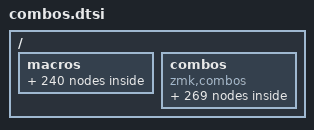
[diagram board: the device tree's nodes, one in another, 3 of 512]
// Chords (combos) for common English words and utility keys
//
// Key position reference (QWERTY) — Ergonaut One 42-key:
//  0(])  1(Q)  2(W)  3(E)  4(R)  5(T)  |  6(Y)  7(U)  8(I)  9(O) 10(P) 11([)
// 12(`) 13(A) 14(S) 15(D) 16(F) 17(G)  | 18(H) 19(J) 20(K) 21(L) 22(;) 23(')
// 24(-) 25(Z) 26(X) 27(C) 28(V) 29(B)  | 30(N) 31(M) 32(,) 33(.) 34(/) 35(\)
//                   36    37    38      | 39    40    41
//
// Letter positions: A=13 B=29 C=27 D=15 E=3 F=16 G=17 H=18 I=8 J=19 K=20
//                   L=21 M=31 N=30 O=9 P=10 Q=1 R=4 S=14 T=5 U=7 V=28
//                   W=2 X=26 Y=6 Z=25
//
// Word combos: timeout-ms=40, require-prior-idle-ms=150, layer 0 only.
// Utility combos: timeout-ms=30, no prior-idle, layer 0 only.
//
// 2-key conflict resolutions (ZMK combos are order-independent):
//   N+T kept as "not", dropped "then" (T+N)
//   T+M kept as "time", dropped "most" (M+T)
//   W+N kept as "when", dropped "new" (N+W)
// 3-key conflict resolutions (6 dropped):
//   Combos sharing identical sorted key sets with a 2-key or another 3-key
//   combo were resolved by keeping the higher-priority entry.

/ {
    macros {
        // === 2-key word macros (58) ===
        m_the: m_the { compatible = "zmk,behavior-macro"; #binding-cells = <0>; wait-ms = <10>; tap-ms = <10>;
            bindings = <&kp T &kp H &kp E &kp SPACE>; };
        m_and: m_and { compatible = "zmk,behavior-macro"; #binding-cells = <0>; wait-ms = <10>; tap-ms = <10>;
            bindings = <&kp A &kp N &kp D &kp SPACE>; };
        m_that: m_that { compatible = "zmk,behavior-macro"; #binding-cells = <0>; wait-ms = <10>; tap-ms = <10>;
            bindings = <&kp T &kp H &kp A &kp T &kp SPACE>; };
        m_have: m_have { compatible = "zmk,behavior-macro"; #binding-cells = <0>; wait-ms = <10>; tap-ms = <10>;
            bindings = <&kp H &kp A &kp V &kp E &kp SPACE>; };
        m_with: m_with { compatible = "zmk,behavior-macro"; #binding-cells = <0>; wait-ms = <10>; tap-ms = <10>;
            bindings = <&kp W &kp I &kp T &kp H &kp SPACE>; };
        m_for: m_for { compatible = "zmk,behavior-macro"; #binding-cells = <0>; wait-ms = <10>; tap-ms = <10>;
            bindings = <&kp F &kp O &kp R &kp SPACE>; };
        m_not: m_not { compatible = "zmk,behavior-macro"; #binding-cells = <0>; wait-ms = <10>; tap-ms = <10>;
            bindings = <&kp N &kp O &kp T &kp SPACE>; };
        m_you: m_you { compatible = "zmk,behavior-macro"; #binding-cells = <0>; wait-ms = <10>; tap-ms = <10>;
            bindings = <&kp Y &kp O &kp U &kp SPACE>; };
        m_this: m_this { compatible = "zmk,behavior-macro"; #binding-cells = <0>; wait-ms = <10>; tap-ms = <10>;
            bindings = <&kp T &kp H &kp I &kp S &kp SPACE>; };
        m_but: m_but { compatible = "zmk,behavior-macro"; #binding-cells = <0>; wait-ms = <10>; tap-ms = <10>;
            bindings = <&kp B &kp U &kp T &kp SPACE>; };
        m_from: m_from { compatible = "zmk,behavior-macro"; #binding-cells = <0>; wait-ms = <10>; tap-ms = <10>;
            bindings = <&kp F &kp R &kp O &kp M &kp SPACE>; };
        m_they: m_they { compatible = "zmk,behavior-macro"; #binding-cells = <0>; wait-ms = <10>; tap-ms = <10>;
            bindings = <&kp T &kp H &kp E &kp Y &kp SPACE>; };
        m_will: m_will { compatible = "zmk,behavior-macro"; #binding-cells = <0>; wait-ms = <10>; tap-ms = <10>;
            bindings = <&kp W &kp I &kp L &kp L &kp SPACE>; };
        m_would: m_would { compatible = "zmk,behavior-macro"; #binding-cells = <0>; wait-ms = <10>; tap-ms = <10>;
            bindings = <&kp W &kp O &kp U &kp L &kp D &kp SPACE>; };
        m_what: m_what { compatible = "zmk,behavior-macro"; #binding-cells = <0>; wait-ms = <10>; tap-ms = <10>;
            bindings = <&kp W &kp H &kp A &kp T &kp SPACE>; };
        m_about: m_about { compatible = "zmk,behavior-macro"; #binding-cells = <0>; wait-ms = <10>; tap-ms = <10>;
            bindings = <&kp A &kp B &kp O &kp U &kp T &kp SPACE>; };
        m_which: m_which { compatible = "zmk,behavior-macro"; #binding-cells = <0>; wait-ms = <10>; tap-ms = <10>;
            bindings = <&kp W &kp H &kp I &kp C &kp H &kp SPACE>; };
        m_when: m_when { compatible = "zmk,behavior-macro"; #binding-cells = <0>; wait-ms = <10>; tap-ms = <10>;
            bindings = <&kp W &kp H &kp E &kp N &kp SPACE>; };
        m_just: m_just { compatible = "zmk,behavior-macro"; #binding-cells = <0>; wait-ms = <10>; tap-ms = <10>;
            bindings = <&kp J &kp U &kp S &kp T &kp SPACE>; };
        m_know: m_know { compatible = "zmk,behavior-macro"; #binding-cells = <0>; wait-ms = <10>; tap-ms = <10>;
            bindings = <&kp K &kp N &kp O &kp W &kp SPACE>; };
        m_like: m_like { compatible = "zmk,behavior-macro"; #binding-cells = <0>; wait-ms = <10>; tap-ms = <10>;
            bindings = <&kp L &kp I &kp K &kp E &kp SPACE>; };
        m_your: m_your { compatible = "zmk,behavior-macro"; #binding-cells = <0>; wait-ms = <10>; tap-ms = <10>;
            bindings = <&kp Y &kp O &kp U &kp R &kp SPACE>; };
        m_could: m_could { compatible = "zmk,behavior-macro"; #binding-cells = <0>; wait-ms = <10>; tap-ms = <10>;
            bindings = <&kp C &kp O &kp U &kp L &kp D &kp SPACE>; };
        m_should: m_should { compatible = "zmk,behavior-macro"; #binding-cells = <0>; wait-ms = <10>; tap-ms = <10>;
            bindings = <&kp S &kp H &kp O &kp U &kp L &kp D &kp SPACE>; };
        m_before: m_before { compatible = "zmk,behavior-macro"; #binding-cells = <0>; wait-ms = <10>; tap-ms = <10>;
            bindings = <&kp B &kp E &kp F &kp O &kp R &kp E &kp SPACE>; };
        m_because: m_because { compatible = "zmk,behavior-macro"; #binding-cells = <0>; wait-ms = <10>; tap-ms = <10>;
            bindings = <&kp B &kp E &kp C &kp A &kp U &kp S &kp E &kp SPACE>; };
        m_think: m_think { compatible = "zmk,behavior-macro"; #binding-cells = <0>; wait-ms = <10>; tap-ms = <10>;
            bindings = <&kp T &kp H &kp I &kp N &kp K &kp SPACE>; };
        m_also: m_also { compatible = "zmk,behavior-macro"; #binding-cells = <0>; wait-ms = <10>; tap-ms = <10>;
            bindings = <&kp A &kp L &kp S &kp O &kp SPACE>; };
        m_after: m_after { compatible = "zmk,behavior-macro"; #binding-cells = <0>; wait-ms = <10>; tap-ms = <10>;
            bindings = <&kp A &kp F &kp T &kp E &kp R &kp SPACE>; };
        m_time: m_time { compatible = "zmk,behavior-macro"; #binding-cells = <0>; wait-ms = <10>; tap-ms = <10>;
            bindings = <&kp T &kp I &kp M &kp E &kp SPACE>; };
        m_again: m_again { compatible = "zmk,behavior-macro"; #binding-cells = <0>; wait-ms = <10>; tap-ms = <10>;
            bindings = <&kp A &kp G &kp A &kp I &kp N &kp SPACE>; };
        m_some: m_some { compatible = "zmk,behavior-macro"; #binding-cells = <0>; wait-ms = <10>; tap-ms = <10>;
            bindings = <&kp S &kp O &kp M &kp E &kp SPACE>; };
        m_good: m_good { compatible = "zmk,behavior-macro"; #binding-cells = <0>; wait-ms = <10>; tap-ms = <10>;
            bindings = <&kp G &kp O &kp O &kp D &kp SPACE>; };
        m_more: m_more { compatible = "zmk,behavior-macro"; #binding-cells = <0>; wait-ms = <10>; tap-ms = <10>;
            bindings = <&kp M &kp O &kp R &kp E &kp SPACE>; };
        m_never: m_never { compatible = "zmk,behavior-macro"; #binding-cells = <0>; wait-ms = <10>; tap-ms = <10>;
            bindings = <&kp N &kp E &kp V &kp E &kp R &kp SPACE>; };
        m_even: m_even { compatible = "zmk,behavior-macro"; #binding-cells = <0>; wait-ms = <10>; tap-ms = <10>;
            bindings = <&kp E &kp V &kp E &kp N &kp SPACE>; };
        m_very: m_very { compatible = "zmk,behavior-macro"; #binding-cells = <0>; wait-ms = <10>; tap-ms = <10>;
            bindings = <&kp V &kp E &kp R &kp Y &kp SPACE>; };
        m_work: m_work { compatible = "zmk,behavior-macro"; #binding-cells = <0>; wait-ms = <10>; tap-ms = <10>;
            bindings = <&kp W &kp O &kp R &kp K &kp SPACE>; };
        m_way: m_way { compatible = "zmk,behavior-macro"; #binding-cells = <0>; wait-ms = <10>; tap-ms = <10>;
            bindings = <&kp W &kp A &kp Y &kp SPACE>; };
        m_make: m_make { compatible = "zmk,behavior-macro"; #binding-cells = <0>; wait-ms = <10>; tap-ms = <10>;
            bindings = <&kp M &kp A &kp K &kp E &kp SPACE>; };
        m_need: m_need { compatible = "zmk,behavior-macro"; #binding-cells = <0>; wait-ms = <10>; tap-ms = <10>;
            bindings = <&kp N &kp E &kp E &kp D &kp SPACE>; };
        m_only: m_only { compatible = "zmk,behavior-macro"; #binding-cells = <0>; wait-ms = <10>; tap-ms = <10>;
            bindings = <&kp O &kp N &kp L &kp Y &kp SPACE>; };
        m_been: m_been { compatible = "zmk,behavior-macro"; #binding-cells = <0>; wait-ms = <10>; tap-ms = <10>;
            bindings = <&kp B &kp E &kp E &kp N &kp SPACE>; };
        m_while: m_while { compatible = "zmk,behavior-macro"; #binding-cells = <0>; wait-ms = <10>; tap-ms = <10>;
            bindings = <&kp W &kp H &kp I &kp L &kp E &kp SPACE>; };
        m_can: m_can { compatible = "zmk,behavior-macro"; #binding-cells = <0>; wait-ms = <10>; tap-ms = <10>;
            bindings = <&kp C &kp A &kp N &kp SPACE>; };
        m_come: m_come { compatible = "zmk,behavior-macro"; #binding-cells = <0>; wait-ms = <10>; tap-ms = <10>;
            bindings = <&kp C &kp O &kp M &kp E &kp SPACE>; };
        m_one: m_one { compatible = "zmk,behavior-macro"; #binding-cells = <0>; wait-ms = <10>; tap-ms = <10>;
            bindings = <&kp O &kp N &kp E &kp SPACE>; };
        m_great: m_great { compatible = "zmk,behavior-macro"; #binding-cells = <0>; wait-ms = <10>; tap-ms = <10>;
            bindings = <&kp G &kp R &kp E &kp A &kp T &kp SPACE>; };
        m_might: m_might { compatible = "zmk,behavior-macro"; #binding-cells = <0>; wait-ms = <10>; tap-ms = <10>;
            bindings = <&kp M &kp I &kp G &kp H &kp T &kp SPACE>; };
        m_found: m_found { compatible = "zmk,behavior-macro"; #binding-cells = <0>; wait-ms = <10>; tap-ms = <10>;
            bindings = <&kp F &kp O &kp U &kp N &kp D &kp SPACE>; };
        m_under: m_under { compatible = "zmk,behavior-macro"; #binding-cells = <0>; wait-ms = <10>; tap-ms = <10>;
            bindings = <&kp U &kp N &kp D &kp E &kp R &kp SPACE>; };
        m_other: m_other { compatible = "zmk,behavior-macro"; #binding-cells = <0>; wait-ms = <10>; tap-ms = <10>;
            bindings = <&kp O &kp T &kp H &kp E &kp R &kp SPACE>; };
        m_people: m_people { compatible = "zmk,behavior-macro"; #binding-cells = <0>; wait-ms = <10>; tap-ms = <10>;
            bindings = <&kp P &kp E &kp O &kp P &kp L &kp E &kp SPACE>; };
        m_really: m_really { compatible = "zmk,behavior-macro"; #binding-cells = <0>; wait-ms = <10>; tap-ms = <10>;
            bindings = <&kp R &kp E &kp A &kp L &kp L &kp Y &kp SPACE>; };
        m_her: m_her { compatible = "zmk,behavior-macro"; #binding-cells = <0>; wait-ms = <10>; tap-ms = <10>;
            bindings = <&kp H &kp E &kp R &kp SPACE>; };
        m_his: m_his { compatible = "zmk,behavior-macro"; #binding-cells = <0>; wait-ms = <10>; tap-ms = <10>;
            bindings = <&kp H &kp I &kp S &kp SPACE>; };
        m_are: m_are { compatible = "zmk,behavior-macro"; #binding-cells = <0>; wait-ms = <10>; tap-ms = <10>;
            bindings = <&kp A &kp R &kp E &kp SPACE>; };
        m_was: m_was { compatible = "zmk,behavior-macro"; #binding-cells = <0>; wait-ms = <10>; tap-ms = <10>;
            bindings = <&kp W &kp A &kp S &kp SPACE>; };

        // === 3-key word macros — Common English (43) ===
        m_through: m_through { compatible = "zmk,behavior-macro"; #binding-cells = <0>; wait-ms = <10>; tap-ms = <10>;
            bindings = <&kp T &kp H &kp R &kp O &kp U &kp G &kp H &kp SPACE>; };
        m_there: m_there { compatible = "zmk,behavior-macro"; #binding-cells = <0>; wait-ms = <10>; tap-ms = <10>;
            bindings = <&kp T &kp H &kp E &kp R &kp E &kp SPACE>; };
        m_than: m_than { compatible = "zmk,behavior-macro"; #binding-cells = <0>; wait-ms = <10>; tap-ms = <10>;
            bindings = <&kp T &kp H &kp A &kp N &kp SPACE>; };
        m_their: m_their { compatible = "zmk,behavior-macro"; #binding-cells = <0>; wait-ms = <10>; tap-ms = <10>;
            bindings = <&kp T &kp H &kp E &kp I &kp R &kp SPACE>; };
        m_those: m_those { compatible = "zmk,behavior-macro"; #binding-cells = <0>; wait-ms = <10>; tap-ms = <10>;
            bindings = <&kp T &kp H &kp O &kp S &kp E &kp SPACE>; };
        m_thing: m_thing { compatible = "zmk,behavior-macro"; #binding-cells = <0>; wait-ms = <10>; tap-ms = <10>;
            bindings = <&kp T &kp H &kp I &kp N &kp G &kp SPACE>; };
        m_though: m_though { compatible = "zmk,behavior-macro"; #binding-cells = <0>; wait-ms = <10>; tap-ms = <10>;
            bindings = <&kp T &kp H &kp O &kp U &kp G &kp H &kp SPACE>; };
        m_three: m_three { compatible = "zmk,behavior-macro"; #binding-cells = <0>; wait-ms = <10>; tap-ms = <10>;
            bindings = <&kp T &kp H &kp R &kp E &kp E &kp SPACE>; };
        m_together: m_together { compatible = "zmk,behavior-macro"; #binding-cells = <0>; wait-ms = <10>; tap-ms = <10>;
            bindings = <&kp T &kp O &kp G &kp E &kp T &kp H &kp E &kp R &kp SPACE>; };
        m_another: m_another { compatible = "zmk,behavior-macro"; #binding-cells = <0>; wait-ms = <10>; tap-ms = <10>;
            bindings = <&kp A &kp N &kp O &kp T &kp H &kp E &kp R &kp SPACE>; };
        m_where: m_where { compatible = "zmk,behavior-macro"; #binding-cells = <0>; wait-ms = <10>; tap-ms = <10>;
            bindings = <&kp W &kp H &kp E &kp R &kp E &kp SPACE>; };
        m_whether: m_whether { compatible = "zmk,behavior-macro"; #binding-cells = <0>; wait-ms = <10>; tap-ms = <10>;
            bindings = <&kp W &kp H &kp E &kp T &kp H &kp E &kp R &kp SPACE>; };
        m_between: m_between { compatible = "zmk,behavior-macro"; #binding-cells = <0>; wait-ms = <10>; tap-ms = <10>;
            bindings = <&kp B &kp E &kp T &kp W &kp E &kp E &kp N &kp SPACE>; };
        m_something: m_something { compatible = "zmk,behavior-macro"; #binding-cells = <0>; wait-ms = <10>; tap-ms = <10>;
            bindings = <&kp S &kp O &kp M &kp E &kp T &kp H &kp I &kp N &kp G &kp SPACE>; };
        m_already: m_already { compatible = "zmk,behavior-macro"; #binding-cells = <0>; wait-ms = <10>; tap-ms = <10>;
            bindings = <&kp A &kp L &kp R &kp E &kp A &kp D &kp Y &kp SPACE>; };
        m_always: m_always { compatible = "zmk,behavior-macro"; #binding-cells = <0>; wait-ms = <10>; tap-ms = <10>;
            bindings = <&kp A &kp L &kp W &kp A &kp Y &kp S &kp SPACE>; };
        m_around: m_around { compatible = "zmk,behavior-macro"; #binding-cells = <0>; wait-ms = <10>; tap-ms = <10>;
            bindings = <&kp A &kp R &kp O &kp U &kp N &kp D &kp SPACE>; };
        m_different: m_different { compatible = "zmk,behavior-macro"; #binding-cells = <0>; wait-ms = <10>; tap-ms = <10>;
            bindings = <&kp D &kp I &kp F &kp F &kp E &kp R &kp E &kp N &kp T &kp SPACE>; };
        m_important: m_important { compatible = "zmk,behavior-macro"; #binding-cells = <0>; wait-ms = <10>; tap-ms = <10>;
            bindings = <&kp I &kp M &kp P &kp O &kp R &kp T &kp A &kp N &kp T &kp SPACE>; };
        m_still: m_still { compatible = "zmk,behavior-macro"; #binding-cells = <0>; wait-ms = <10>; tap-ms = <10>;
            bindings = <&kp S &kp T &kp I &kp L &kp L &kp SPACE>; };
        m_every: m_every { compatible = "zmk,behavior-macro"; #binding-cells = <0>; wait-ms = <10>; tap-ms = <10>;
            bindings = <&kp E &kp V &kp E &kp R &kp Y &kp SPACE>; };
        m_first: m_first { compatible = "zmk,behavior-macro"; #binding-cells = <0>; wait-ms = <10>; tap-ms = <10>;
            bindings = <&kp F &kp I &kp R &kp S &kp T &kp SPACE>; };
        m_world: m_world { compatible = "zmk,behavior-macro"; #binding-cells = <0>; wait-ms = <10>; tap-ms = <10>;
            bindings = <&kp W &kp O &kp R &kp L &kp D &kp SPACE>; };
        m_little: m_little { compatible = "zmk,behavior-macro"; #binding-cells = <0>; wait-ms = <10>; tap-ms = <10>;
            bindings = <&kp L &kp I &kp T &kp T &kp L &kp E &kp SPACE>; };
        m_right: m_right { compatible = "zmk,behavior-macro"; #binding-cells = <0>; wait-ms = <10>; tap-ms = <10>;
            bindings = <&kp R &kp I &kp G &kp H &kp T &kp SPACE>; };
        m_being: m_being { compatible = "zmk,behavior-macro"; #binding-cells = <0>; wait-ms = <10>; tap-ms = <10>;
            bindings = <&kp B &kp E &kp I &kp N &kp G &kp SPACE>; };
        m_small: m_small { compatible = "zmk,behavior-macro"; #binding-cells = <0>; wait-ms = <10>; tap-ms = <10>;
            bindings = <&kp S &kp M &kp A &kp L &kp L &kp SPACE>; };
        m_take: m_take { compatible = "zmk,behavior-macro"; #binding-cells = <0>; wait-ms = <10>; tap-ms = <10>;
            bindings = <&kp T &kp A &kp K &kp E &kp SPACE>; };
        m_well: m_well { compatible = "zmk,behavior-macro"; #binding-cells = <0>; wait-ms = <10>; tap-ms = <10>;
            bindings = <&kp W &kp E &kp L &kp L &kp SPACE>; };
        m_into: m_into { compatible = "zmk,behavior-macro"; #binding-cells = <0>; wait-ms = <10>; tap-ms = <10>;
            bindings = <&kp I &kp N &kp T &kp O &kp SPACE>; };
        m_here: m_here { compatible = "zmk,behavior-macro"; #binding-cells = <0>; wait-ms = <10>; tap-ms = <10>;
            bindings = <&kp H &kp E &kp R &kp E &kp SPACE>; };
        m_since: m_since { compatible = "zmk,behavior-macro"; #binding-cells = <0>; wait-ms = <10>; tap-ms = <10>;
            bindings = <&kp S &kp I &kp N &kp C &kp E &kp SPACE>; };
        m_story: m_story { compatible = "zmk,behavior-macro"; #binding-cells = <0>; wait-ms = <10>; tap-ms = <10>;
            bindings = <&kp S &kp T &kp O &kp R &kp Y &kp SPACE>; };
        m_write: m_write { compatible = "zmk,behavior-macro"; #binding-cells = <0>; wait-ms = <10>; tap-ms = <10>;
            bindings = <&kp W &kp R &kp I &kp T &kp E &kp SPACE>; };
        m_using: m_using { compatible = "zmk,behavior-macro"; #binding-cells = <0>; wait-ms = <10>; tap-ms = <10>;
            bindings = <&kp U &kp S &kp I &kp N &kp G &kp SPACE>; };
        m_actually: m_actually { compatible = "zmk,behavior-macro"; #binding-cells = <0>; wait-ms = <10>; tap-ms = <10>;
            bindings = <&kp A &kp C &kp T &kp U &kp A &kp L &kp L &kp Y &kp SPACE>; };
        m_learn: m_learn { compatible = "zmk,behavior-macro"; #binding-cells = <0>; wait-ms = <10>; tap-ms = <10>;
            bindings = <&kp L &kp E &kp A &kp R &kp N &kp SPACE>; };
        m_point: m_point { compatible = "zmk,behavior-macro"; #binding-cells = <0>; wait-ms = <10>; tap-ms = <10>;
            bindings = <&kp P &kp O &kp I &kp N &kp T &kp SPACE>; };
        m_long: m_long { compatible = "zmk,behavior-macro"; #binding-cells = <0>; wait-ms = <10>; tap-ms = <10>;
            bindings = <&kp L &kp O &kp N &kp G &kp SPACE>; };
        m_keep: m_keep { compatible = "zmk,behavior-macro"; #binding-cells = <0>; wait-ms = <10>; tap-ms = <10>;
            bindings = <&kp K &kp E &kp E &kp P &kp SPACE>; };
        m_same: m_same { compatible = "zmk,behavior-macro"; #binding-cells = <0>; wait-ms = <10>; tap-ms = <10>;
            bindings = <&kp S &kp A &kp M &kp E &kp SPACE>; };
        m_each: m_each { compatible = "zmk,behavior-macro"; #binding-cells = <0>; wait-ms = <10>; tap-ms = <10>;
            bindings = <&kp E &kp A &kp C &kp H &kp SPACE>; };
        m_help: m_help { compatible = "zmk,behavior-macro"; #binding-cells = <0>; wait-ms = <10>; tap-ms = <10>;
            bindings = <&kp H &kp E &kp L &kp P &kp SPACE>; };

        // === 3-key word macros — ML/AI (23) ===
        m_diffusion: m_diffusion { compatible = "zmk,behavior-macro"; #binding-cells = <0>; wait-ms = <10>; tap-ms = <10>;
            bindings = <&kp D &kp I &kp F &kp F &kp U &kp S &kp I &kp O &kp N &kp SPACE>; };
        m_embedding: m_embedding { compatible = "zmk,behavior-macro"; #binding-cells = <0>; wait-ms = <10>; tap-ms = <10>;
            bindings = <&kp E &kp M &kp B &kp E &kp D &kp D &kp I &kp N &kp G &kp SPACE>; };
        m_gradient: m_gradient { compatible = "zmk,behavior-macro"; #binding-cells = <0>; wait-ms = <10>; tap-ms = <10>;
            bindings = <&kp G &kp R &kp A &kp D &kp I &kp E &kp N &kp T &kp SPACE>; };
        m_inference: m_inference { compatible = "zmk,behavior-macro"; #binding-cells = <0>; wait-ms = <10>; tap-ms = <10>;
            bindings = <&kp I &kp N &kp F &kp E &kp R &kp E &kp N &kp C &kp E &kp SPACE>; };
        m_training: m_training { compatible = "zmk,behavior-macro"; #binding-cells = <0>; wait-ms = <10>; tap-ms = <10>;
            bindings = <&kp T &kp R &kp A &kp I &kp N &kp I &kp N &kp G &kp SPACE>; };
        m_activation: m_activation { compatible = "zmk,behavior-macro"; #binding-cells = <0>; wait-ms = <10>; tap-ms = <10>;
            bindings = <&kp A &kp C &kp T &kp I &kp V &kp A &kp T &kp I &kp O &kp N &kp SPACE>; };
        m_backprop: m_backprop { compatible = "zmk,behavior-macro"; #binding-cells = <0>; wait-ms = <10>; tap-ms = <10>;
            bindings = <&kp B &kp A &kp C &kp K &kp P &kp R &kp O &kp P &kp SPACE>; };
        m_neural: m_neural { compatible = "zmk,behavior-macro"; #binding-cells = <0>; wait-ms = <10>; tap-ms = <10>;
            bindings = <&kp N &kp E &kp U &kp R &kp A &kp L &kp SPACE>; };
        m_dropout: m_dropout { compatible = "zmk,behavior-macro"; #binding-cells = <0>; wait-ms = <10>; tap-ms = <10>;
            bindings = <&kp D &kp R &kp O &kp P &kp O &kp U &kp T &kp SPACE>; };
        m_dataset: m_dataset { compatible = "zmk,behavior-macro"; #binding-cells = <0>; wait-ms = <10>; tap-ms = <10>;
            bindings = <&kp D &kp A &kp T &kp A &kp S &kp E &kp T &kp SPACE>; };
        m_tokenize: m_tokenize { compatible = "zmk,behavior-macro"; #binding-cells = <0>; wait-ms = <10>; tap-ms = <10>;
            bindings = <&kp T &kp O &kp K &kp E &kp N &kp I &kp Z &kp E &kp SPACE>; };
        m_latent: m_latent { compatible = "zmk,behavior-macro"; #binding-cells = <0>; wait-ms = <10>; tap-ms = <10>;
            bindings = <&kp L &kp A &kp T &kp E &kp N &kp T &kp SPACE>; };
        m_softmax: m_softmax { compatible = "zmk,behavior-macro"; #binding-cells = <0>; wait-ms = <10>; tap-ms = <10>;
            bindings = <&kp S &kp O &kp F &kp T &kp M &kp A &kp X &kp SPACE>; };
        m_residual: m_residual { compatible = "zmk,behavior-macro"; #binding-cells = <0>; wait-ms = <10>; tap-ms = <10>;
            bindings = <&kp R &kp E &kp S &kp I &kp D &kp U &kp A &kp L &kp SPACE>; };
        m_checkpoint: m_checkpoint { compatible = "zmk,behavior-macro"; #binding-cells = <0>; wait-ms = <10>; tap-ms = <10>;
            bindings = <&kp C &kp H &kp E &kp C &kp K &kp P &kp O &kp I &kp N &kp T &kp SPACE>; };
        m_logit: m_logit { compatible = "zmk,behavior-macro"; #binding-cells = <0>; wait-ms = <10>; tap-ms = <10>;
            bindings = <&kp L &kp O &kp G &kp I &kp T &kp SPACE>; };
        m_epoch: m_epoch { compatible = "zmk,behavior-macro"; #binding-cells = <0>; wait-ms = <10>; tap-ms = <10>;
            bindings = <&kp E &kp P &kp O &kp C &kp H &kp SPACE>; };
        m_batch: m_batch { compatible = "zmk,behavior-macro"; #binding-cells = <0>; wait-ms = <10>; tap-ms = <10>;
            bindings = <&kp B &kp A &kp T &kp C &kp H &kp SPACE>; };
        m_model: m_model { compatible = "zmk,behavior-macro"; #binding-cells = <0>; wait-ms = <10>; tap-ms = <10>;
            bindings = <&kp M &kp O &kp D &kp E &kp L &kp SPACE>; };
        m_language: m_language { compatible = "zmk,behavior-macro"; #binding-cells = <0>; wait-ms = <10>; tap-ms = <10>;
            bindings = <&kp L &kp A &kp N &kp G &kp U &kp A &kp G &kp E &kp SPACE>; };
        m_parameter: m_parameter { compatible = "zmk,behavior-macro"; #binding-cells = <0>; wait-ms = <10>; tap-ms = <10>;
            bindings = <&kp P &kp A &kp R &kp A &kp M &kp E &kp T &kp E &kp R &kp SPACE>; };
        m_mamba: m_mamba { compatible = "zmk,behavior-macro"; #binding-cells = <0>; wait-ms = <10>; tap-ms = <10>;
            bindings = <&kp M &kp A &kp M &kp B &kp A &kp SPACE>; };
        m_convolutional: m_convolutional { compatible = "zmk,behavior-macro"; #binding-cells = <0>; wait-ms = <10>; tap-ms = <10>;
            bindings = <&kp C &kp O &kp N &kp V &kp O &kp L &kp U &kp T &kp I &kp O &kp N &kp A &kp L &kp SPACE>; };

        // === 3-key word macros — Rust (13) ===
        m_trait: m_trait { compatible = "zmk,behavior-macro"; #binding-cells = <0>; wait-ms = <10>; tap-ms = <10>;
            bindings = <&kp T &kp R &kp A &kp I &kp T &kp SPACE>; };
        m_await: m_await { compatible = "zmk,behavior-macro"; #binding-cells = <0>; wait-ms = <10>; tap-ms = <10>;
            bindings = <&kp A &kp W &kp A &kp I &kp T &kp SPACE>; };
        m_impl: m_impl { compatible = "zmk,behavior-macro"; #binding-cells = <0>; wait-ms = <10>; tap-ms = <10>;
            bindings = <&kp I &kp M &kp P &kp L &kp SPACE>; };
        m_result: m_result { compatible = "zmk,behavior-macro"; #binding-cells = <0>; wait-ms = <10>; tap-ms = <10>;
            bindings = <&kp LS(R) &kp E &kp S &kp U &kp L &kp T &kp LESS_THAN>; };
        m_option: m_option { compatible = "zmk,behavior-macro"; #binding-cells = <0>; wait-ms = <10>; tap-ms = <10>;
            bindings = <&kp LS(O) &kp P &kp T &kp I &kp O &kp N &kp LESS_THAN>; };
        m_enum: m_enum { compatible = "zmk,behavior-macro"; #binding-cells = <0>; wait-ms = <10>; tap-ms = <10>;
            bindings = <&kp E &kp N &kp U &kp M &kp SPACE>; };
        m_match: m_match { compatible = "zmk,behavior-macro"; #binding-cells = <0>; wait-ms = <10>; tap-ms = <10>;
            bindings = <&kp M &kp A &kp T &kp C &kp H &kp SPACE>; };
        m_return: m_return { compatible = "zmk,behavior-macro"; #binding-cells = <0>; wait-ms = <10>; tap-ms = <10>;
            bindings = <&kp R &kp E &kp T &kp U &kp R &kp N &kp SPACE>; };
        m_derive: m_derive { compatible = "zmk,behavior-macro"; #binding-cells = <0>; wait-ms = <10>; tap-ms = <10>;
            bindings = <&kp D &kp E &kp R &kp I &kp V &kp E &kp SPACE>; };
        m_closure: m_closure { compatible = "zmk,behavior-macro"; #binding-cells = <0>; wait-ms = <10>; tap-ms = <10>;
            bindings = <&kp C &kp L &kp O &kp S &kp U &kp R &kp E &kp SPACE>; };
        m_lifetime: m_lifetime { compatible = "zmk,behavior-macro"; #binding-cells = <0>; wait-ms = <10>; tap-ms = <10>;
            bindings = <&kp L &kp I &kp F &kp E &kp T &kp I &kp M &kp E &kp SPACE>; };
        m_borrow: m_borrow { compatible = "zmk,behavior-macro"; #binding-cells = <0>; wait-ms = <10>; tap-ms = <10>;
            bindings = <&kp B &kp O &kp R &kp R &kp O &kp W &kp SPACE>; };
        m_mut: m_mut { compatible = "zmk,behavior-macro"; #binding-cells = <0>; wait-ms = <10>; tap-ms = <10>;
            bindings = <&kp M &kp U &kp T &kp SPACE>; };

        // === 3-key word macros — Haskell (6) ===
        m_monad: m_monad { compatible = "zmk,behavior-macro"; #binding-cells = <0>; wait-ms = <10>; tap-ms = <10>;
            bindings = <&kp M &kp O &kp N &kp A &kp D &kp SPACE>; };
        m_functor: m_functor { compatible = "zmk,behavior-macro"; #binding-cells = <0>; wait-ms = <10>; tap-ms = <10>;
            bindings = <&kp F &kp U &kp N &kp C &kp T &kp O &kp R &kp SPACE>; };
        m_maybe: m_maybe { compatible = "zmk,behavior-macro"; #binding-cells = <0>; wait-ms = <10>; tap-ms = <10>;
            bindings = <&kp LS(M) &kp A &kp Y &kp B &kp E &kp SPACE>; };
        m_monoid: m_monoid { compatible = "zmk,behavior-macro"; #binding-cells = <0>; wait-ms = <10>; tap-ms = <10>;
            bindings = <&kp M &kp O &kp N &kp O &kp I &kp D &kp SPACE>; };
        m_lambda: m_lambda { compatible = "zmk,behavior-macro"; #binding-cells = <0>; wait-ms = <10>; tap-ms = <10>;
            bindings = <&kp L &kp A &kp M &kp B &kp D &kp A &kp SPACE>; };
        m_typeclass: m_typeclass { compatible = "zmk,behavior-macro"; #binding-cells = <0>; wait-ms = <10>; tap-ms = <10>;
            bindings = <&kp T &kp Y &kp P &kp E &kp C &kp L &kp A &kp S &kp S &kp SPACE>; };

        // === 3-key word macros — Other (6) ===
        m_function: m_function { compatible = "zmk,behavior-macro"; #binding-cells = <0>; wait-ms = <10>; tap-ms = <10>;
            bindings = <&kp F &kp U &kp N &kp C &kp T &kp I &kp O &kp N &kp SPACE>; };
        m_claude: m_claude { compatible = "zmk,behavior-macro"; #binding-cells = <0>; wait-ms = <10>; tap-ms = <10>;
            bindings = <&kp LS(C) &kp L &kp A &kp U &kp D &kp E &kp SPACE>; };
        m_anthropic: m_anthropic { compatible = "zmk,behavior-macro"; #binding-cells = <0>; wait-ms = <10>; tap-ms = <10>;
            bindings = <&kp LS(A) &kp N &kp T &kp H &kp R &kp O &kp P &kp I &kp C &kp SPACE>; };
        m_azure: m_azure { compatible = "zmk,behavior-macro"; #binding-cells = <0>; wait-ms = <10>; tap-ms = <10>;
            bindings = <&kp LS(A) &kp Z &kp U &kp R &kp E &kp SPACE>; };
        m_duckdb: m_duckdb { compatible = "zmk,behavior-macro"; #binding-cells = <0>; wait-ms = <10>; tap-ms = <10>;
            bindings = <&kp D &kp U &kp C &kp K &kp D &kp B &kp SPACE>; };
        m_iceberg: m_iceberg { compatible = "zmk,behavior-macro"; #binding-cells = <0>; wait-ms = <10>; tap-ms = <10>;
            bindings = <&kp I &kp C &kp E &kp B &kp E &kp R &kp G &kp SPACE>; };

        // === 4-key word macros (10) ===
        m_transformer: m_transformer { compatible = "zmk,behavior-macro"; #binding-cells = <0>; wait-ms = <10>; tap-ms = <10>;
            bindings = <&kp T &kp R &kp A &kp N &kp S &kp F &kp O &kp R &kp M &kp E &kp R &kp SPACE>; };
        m_quantization: m_quantization { compatible = "zmk,behavior-macro"; #binding-cells = <0>; wait-ms = <10>; tap-ms = <10>;
            bindings = <&kp Q &kp U &kp A &kp N &kp T &kp I &kp Z &kp A &kp T &kp I &kp O &kp N &kp SPACE>; };
        m_implementation: m_implementation { compatible = "zmk,behavior-macro"; #binding-cells = <0>; wait-ms = <10>; tap-ms = <10>;
            bindings = <&kp I &kp M &kp P &kp L &kp E &kp M &kp E &kp N &kp T &kp A &kp T &kp I &kp O &kp N &kp SPACE>; };
        m_struct: m_struct { compatible = "zmk,behavior-macro"; #binding-cells = <0>; wait-ms = <10>; tap-ms = <10>;
            bindings = <&kp S &kp T &kp R &kp U &kp C &kp T &kp SPACE>; };
        m_async: m_async { compatible = "zmk,behavior-macro"; #binding-cells = <0>; wait-ms = <10>; tap-ms = <10>;
            bindings = <&kp A &kp S &kp Y &kp N &kp C &kp SPACE>; };
        m_haskell: m_haskell { compatible = "zmk,behavior-macro"; #binding-cells = <0>; wait-ms = <10>; tap-ms = <10>;
            bindings = <&kp H &kp A &kp S &kp K &kp E &kp L &kp L &kp SPACE>; };
        m_forall: m_forall { compatible = "zmk,behavior-macro"; #binding-cells = <0>; wait-ms = <10>; tap-ms = <10>;
            bindings = <&kp F &kp O &kp R &kp A &kp L &kp L &kp SPACE>; };
        m_skinly: m_skinly { compatible = "zmk,behavior-macro"; #binding-cells = <0>; wait-ms = <10>; tap-ms = <10>;
            bindings = <&kp LS(S) &kp K &kp I &kp N &kp L &kp Y &kp SPACE>; };
        m_beiersdorf: m_beiersdorf { compatible = "zmk,behavior-macro"; #binding-cells = <0>; wait-ms = <10>; tap-ms = <10>;
            bindings = <&kp LS(B) &kp E &kp I &kp E &kp R &kp S &kp D &kp O &kp R &kp F &kp SPACE>; };
        m_architecture: m_architecture { compatible = "zmk,behavior-macro"; #binding-cells = <0>; wait-ms = <10>; tap-ms = <10>;
            bindings = <&kp A &kp R &kp C &kp H &kp I &kp T &kp E &kp C &kp T &kp U &kp R &kp E &kp SPACE>; };

        m_said: m_said { compatible = "zmk,behavior-macro"; #binding-cells = <0>; wait-ms = <10>; tap-ms = <10>;
            bindings = <&kp S &kp A &kp I &kp D &kp SPACE>; };
        m_look: m_look { compatible = "zmk,behavior-macro"; #binding-cells = <0>; wait-ms = <10>; tap-ms = <10>;
            bindings = <&kp L &kp O &kp O &kp K &kp SPACE>; };
        m_want: m_want { compatible = "zmk,behavior-macro"; #binding-cells = <0>; wait-ms = <10>; tap-ms = <10>;
            bindings = <&kp W &kp A &kp N &kp T &kp SPACE>; };
        m_give: m_give { compatible = "zmk,behavior-macro"; #binding-cells = <0>; wait-ms = <10>; tap-ms = <10>;
            bindings = <&kp G &kp I &kp V &kp E &kp SPACE>; };
        m_find: m_find { compatible = "zmk,behavior-macro"; #binding-cells = <0>; wait-ms = <10>; tap-ms = <10>;
            bindings = <&kp F &kp I &kp N &kp D &kp SPACE>; };
        m_tell: m_tell { compatible = "zmk,behavior-macro"; #binding-cells = <0>; wait-ms = <10>; tap-ms = <10>;
            bindings = <&kp T &kp E &kp L &kp L &kp SPACE>; };
        m_seem: m_seem { compatible = "zmk,behavior-macro"; #binding-cells = <0>; wait-ms = <10>; tap-ms = <10>;
            bindings = <&kp S &kp E &kp E &kp M &kp SPACE>; };
        m_feel: m_feel { compatible = "zmk,behavior-macro"; #binding-cells = <0>; wait-ms = <10>; tap-ms = <10>;
            bindings = <&kp F &kp E &kp E &kp L &kp SPACE>; };
        m_leave: m_leave { compatible = "zmk,behavior-macro"; #binding-cells = <0>; wait-ms = <10>; tap-ms = <10>;
            bindings = <&kp L &kp E &kp A &kp V &kp E &kp SPACE>; };
        m_call: m_call { compatible = "zmk,behavior-macro"; #binding-cells = <0>; wait-ms = <10>; tap-ms = <10>;
            bindings = <&kp C &kp A &kp L &kp L &kp SPACE>; };
        m_start: m_start { compatible = "zmk,behavior-macro"; #binding-cells = <0>; wait-ms = <10>; tap-ms = <10>;
            bindings = <&kp S &kp T &kp A &kp R &kp T &kp SPACE>; };
        m_show: m_show { compatible = "zmk,behavior-macro"; #binding-cells = <0>; wait-ms = <10>; tap-ms = <10>;
            bindings = <&kp S &kp H &kp O &kp W &kp SPACE>; };
        m_hear: m_hear { compatible = "zmk,behavior-macro"; #binding-cells = <0>; wait-ms = <10>; tap-ms = <10>;
            bindings = <&kp H &kp E &kp A &kp R &kp SPACE>; };
        m_play: m_play { compatible = "zmk,behavior-macro"; #binding-cells = <0>; wait-ms = <10>; tap-ms = <10>;
            bindings = <&kp P &kp L &kp A &kp Y &kp SPACE>; };
        m_move: m_move { compatible = "zmk,behavior-macro"; #binding-cells = <0>; wait-ms = <10>; tap-ms = <10>;
            bindings = <&kp M &kp O &kp V &kp E &kp SPACE>; };
        m_believe: m_believe { compatible = "zmk,behavior-macro"; #binding-cells = <0>; wait-ms = <10>; tap-ms = <10>;
            bindings = <&kp B &kp E &kp L &kp I &kp E &kp V &kp E &kp SPACE>; };
        m_hold: m_hold { compatible = "zmk,behavior-macro"; #binding-cells = <0>; wait-ms = <10>; tap-ms = <10>;
            bindings = <&kp H &kp O &kp L &kp D &kp SPACE>; };
        m_begin: m_begin { compatible = "zmk,behavior-macro"; #binding-cells = <0>; wait-ms = <10>; tap-ms = <10>;
            bindings = <&kp B &kp E &kp G &kp I &kp N &kp SPACE>; };
        m_talk: m_talk { compatible = "zmk,behavior-macro"; #binding-cells = <0>; wait-ms = <10>; tap-ms = <10>;
            bindings = <&kp T &kp A &kp L &kp K &kp SPACE>; };
        m_turn: m_turn { compatible = "zmk,behavior-macro"; #binding-cells = <0>; wait-ms = <10>; tap-ms = <10>;
            bindings = <&kp T &kp U &kp R &kp N &kp SPACE>; };
        m_must: m_must { compatible = "zmk,behavior-macro"; #binding-cells = <0>; wait-ms = <10>; tap-ms = <10>;
            bindings = <&kp M &kp U &kp S &kp T &kp SPACE>; };
        m_much: m_much { compatible = "zmk,behavior-macro"; #binding-cells = <0>; wait-ms = <10>; tap-ms = <10>;
            bindings = <&kp M &kp U &kp C &kp H &kp SPACE>; };
        m_many: m_many { compatible = "zmk,behavior-macro"; #binding-cells = <0>; wait-ms = <10>; tap-ms = <10>;
            bindings = <&kp M &kp A &kp N &kp Y &kp SPACE>; };
        m_name: m_name { compatible = "zmk,behavior-macro"; #binding-cells = <0>; wait-ms = <10>; tap-ms = <10>;
            bindings = <&kp N &kp A &kp M &kp E &kp SPACE>; };
        m_less: m_less { compatible = "zmk,behavior-macro"; #binding-cells = <0>; wait-ms = <10>; tap-ms = <10>;
            bindings = <&kp L &kp E &kp S &kp S &kp SPACE>; };
        m_number: m_number { compatible = "zmk,behavior-macro"; #binding-cells = <0>; wait-ms = <10>; tap-ms = <10>;
            bindings = <&kp N &kp U &kp M &kp B &kp E &kp R &kp SPACE>; };
        m_part: m_part { compatible = "zmk,behavior-macro"; #binding-cells = <0>; wait-ms = <10>; tap-ms = <10>;
            bindings = <&kp P &kp A &kp R &kp T &kp SPACE>; };
        m_place: m_place { compatible = "zmk,behavior-macro"; #binding-cells = <0>; wait-ms = <10>; tap-ms = <10>;
            bindings = <&kp P &kp L &kp A &kp C &kp E &kp SPACE>; };
        m_down: m_down { compatible = "zmk,behavior-macro"; #binding-cells = <0>; wait-ms = <10>; tap-ms = <10>;
            bindings = <&kp D &kp O &kp W &kp N &kp SPACE>; };
        m_left: m_left { compatible = "zmk,behavior-macro"; #binding-cells = <0>; wait-ms = <10>; tap-ms = <10>;
            bindings = <&kp L &kp E &kp F &kp T &kp SPACE>; };
        m_problem: m_problem { compatible = "zmk,behavior-macro"; #binding-cells = <0>; wait-ms = <10>; tap-ms = <10>;
            bindings = <&kp P &kp R &kp O &kp B &kp L &kp E &kp M &kp SPACE>; };
        m_hand: m_hand { compatible = "zmk,behavior-macro"; #binding-cells = <0>; wait-ms = <10>; tap-ms = <10>;
            bindings = <&kp H &kp A &kp N &kp D &kp SPACE>; };
        m_case: m_case { compatible = "zmk,behavior-macro"; #binding-cells = <0>; wait-ms = <10>; tap-ms = <10>;
            bindings = <&kp C &kp A &kp S &kp E &kp SPACE>; };
        m_early: m_early { compatible = "zmk,behavior-macro"; #binding-cells = <0>; wait-ms = <10>; tap-ms = <10>;
            bindings = <&kp E &kp A &kp R &kp L &kp Y &kp SPACE>; };
        m_change: m_change { compatible = "zmk,behavior-macro"; #binding-cells = <0>; wait-ms = <10>; tap-ms = <10>;
            bindings = <&kp C &kp H &kp A &kp N &kp G &kp E &kp SPACE>; };
        m_kind: m_kind { compatible = "zmk,behavior-macro"; #binding-cells = <0>; wait-ms = <10>; tap-ms = <10>;
            bindings = <&kp K &kp I &kp N &kp D &kp SPACE>; };
        m_next: m_next { compatible = "zmk,behavior-macro"; #binding-cells = <0>; wait-ms = <10>; tap-ms = <10>;
            bindings = <&kp N &kp E &kp X &kp T &kp SPACE>; };
        m_both: m_both { compatible = "zmk,behavior-macro"; #binding-cells = <0>; wait-ms = <10>; tap-ms = <10>;
            bindings = <&kp B &kp O &kp T &kp H &kp SPACE>; };
        m_social: m_social { compatible = "zmk,behavior-macro"; #binding-cells = <0>; wait-ms = <10>; tap-ms = <10>;
            bindings = <&kp S &kp O &kp C &kp I &kp A &kp L &kp SPACE>; };
        m_doing: m_doing { compatible = "zmk,behavior-macro"; #binding-cells = <0>; wait-ms = <10>; tap-ms = <10>;
            bindings = <&kp D &kp O &kp I &kp N &kp G &kp SPACE>; };
        m_going: m_going { compatible = "zmk,behavior-macro"; #binding-cells = <0>; wait-ms = <10>; tap-ms = <10>;
            bindings = <&kp G &kp O &kp I &kp N &kp G &kp SPACE>; };
        m_possible: m_possible { compatible = "zmk,behavior-macro"; #binding-cells = <0>; wait-ms = <10>; tap-ms = <10>;
            bindings = <&kp P &kp O &kp S &kp S &kp I &kp B &kp L &kp E &kp SPACE>; };
        m_general: m_general { compatible = "zmk,behavior-macro"; #binding-cells = <0>; wait-ms = <10>; tap-ms = <10>;
            bindings = <&kp G &kp E &kp N &kp E &kp R &kp A &kp L &kp SPACE>; };
        m_school: m_school { compatible = "zmk,behavior-macro"; #binding-cells = <0>; wait-ms = <10>; tap-ms = <10>;
            bindings = <&kp S &kp C &kp H &kp O &kp O &kp L &kp SPACE>; };
        m_high: m_high { compatible = "zmk,behavior-macro"; #binding-cells = <0>; wait-ms = <10>; tap-ms = <10>;
            bindings = <&kp H &kp I &kp G &kp H &kp SPACE>; };
        m_business: m_business { compatible = "zmk,behavior-macro"; #binding-cells = <0>; wait-ms = <10>; tap-ms = <10>;
            bindings = <&kp B &kp U &kp S &kp I &kp N &kp E &kp S &kp S &kp SPACE>; };
        m_issue: m_issue { compatible = "zmk,behavior-macro"; #binding-cells = <0>; wait-ms = <10>; tap-ms = <10>;
            bindings = <&kp I &kp S &kp S &kp U &kp E &kp SPACE>; };
        m_side: m_side { compatible = "zmk,behavior-macro"; #binding-cells = <0>; wait-ms = <10>; tap-ms = <10>;
            bindings = <&kp S &kp I &kp D &kp E &kp SPACE>; };
        m_public: m_public { compatible = "zmk,behavior-macro"; #binding-cells = <0>; wait-ms = <10>; tap-ms = <10>;
            bindings = <&kp P &kp U &kp B &kp L &kp I &kp C &kp SPACE>; };
        m_market: m_market { compatible = "zmk,behavior-macro"; #binding-cells = <0>; wait-ms = <10>; tap-ms = <10>;
            bindings = <&kp M &kp A &kp R &kp K &kp E &kp T &kp SPACE>; };
        m_sense: m_sense { compatible = "zmk,behavior-macro"; #binding-cells = <0>; wait-ms = <10>; tap-ms = <10>;
            bindings = <&kp S &kp E &kp N &kp S &kp E &kp SPACE>; };
        m_program: m_program { compatible = "zmk,behavior-macro"; #binding-cells = <0>; wait-ms = <10>; tap-ms = <10>;
            bindings = <&kp P &kp R &kp O &kp G &kp R &kp A &kp M &kp SPACE>; };
        m_question: m_question { compatible = "zmk,behavior-macro"; #binding-cells = <0>; wait-ms = <10>; tap-ms = <10>;
            bindings = <&kp Q &kp U &kp E &kp S &kp T &kp I &kp O &kp N &kp SPACE>; };
        m_government: m_government { compatible = "zmk,behavior-macro"; #binding-cells = <0>; wait-ms = <10>; tap-ms = <10>;
            bindings = <&kp G &kp O &kp V &kp E &kp R &kp N &kp M &kp E &kp N &kp T &kp SPACE>; };
        m_company: m_company { compatible = "zmk,behavior-macro"; #binding-cells = <0>; wait-ms = <10>; tap-ms = <10>;
            bindings = <&kp C &kp O &kp M &kp P &kp A &kp N &kp Y &kp SPACE>; };
        m_week: m_week { compatible = "zmk,behavior-macro"; #binding-cells = <0>; wait-ms = <10>; tap-ms = <10>;
            bindings = <&kp W &kp E &kp E &kp K &kp SPACE>; };
        m_family: m_family { compatible = "zmk,behavior-macro"; #binding-cells = <0>; wait-ms = <10>; tap-ms = <10>;
            bindings = <&kp F &kp A &kp M &kp I &kp L &kp Y &kp SPACE>; };
        m_service: m_service { compatible = "zmk,behavior-macro"; #binding-cells = <0>; wait-ms = <10>; tap-ms = <10>;
            bindings = <&kp S &kp E &kp R &kp V &kp I &kp C &kp E &kp SPACE>; };
        m_friend: m_friend { compatible = "zmk,behavior-macro"; #binding-cells = <0>; wait-ms = <10>; tap-ms = <10>;
            bindings = <&kp F &kp R &kp I &kp E &kp N &kp D &kp SPACE>; };
        m_price: m_price { compatible = "zmk,behavior-macro"; #binding-cells = <0>; wait-ms = <10>; tap-ms = <10>;
            bindings = <&kp P &kp R &kp I &kp C &kp E &kp SPACE>; };
        m_report: m_report { compatible = "zmk,behavior-macro"; #binding-cells = <0>; wait-ms = <10>; tap-ms = <10>;
            bindings = <&kp R &kp E &kp P &kp O &kp R &kp T &kp SPACE>; };
        m_economy: m_economy { compatible = "zmk,behavior-macro"; #binding-cells = <0>; wait-ms = <10>; tap-ms = <10>;
            bindings = <&kp E &kp C &kp O &kp N &kp O &kp M &kp Y &kp SPACE>; };
        m_industry: m_industry { compatible = "zmk,behavior-macro"; #binding-cells = <0>; wait-ms = <10>; tap-ms = <10>;
            bindings = <&kp I &kp N &kp D &kp U &kp S &kp T &kp R &kp Y &kp SPACE>; };
        m_media: m_media { compatible = "zmk,behavior-macro"; #binding-cells = <0>; wait-ms = <10>; tap-ms = <10>;
            bindings = <&kp M &kp E &kp D &kp I &kp A &kp SPACE>; };
        m_practice: m_practice { compatible = "zmk,behavior-macro"; #binding-cells = <0>; wait-ms = <10>; tap-ms = <10>;
            bindings = <&kp P &kp R &kp A &kp C &kp T &kp I &kp C &kp E &kp SPACE>; };
        m_education: m_education { compatible = "zmk,behavior-macro"; #binding-cells = <0>; wait-ms = <10>; tap-ms = <10>;
            bindings = <&kp E &kp D &kp U &kp C &kp A &kp T &kp I &kp O &kp N &kp SPACE>; };
        m_management: m_management { compatible = "zmk,behavior-macro"; #binding-cells = <0>; wait-ms = <10>; tap-ms = <10>;
            bindings = <&kp M &kp A &kp N &kp A &kp G &kp E &kp M &kp E &kp N &kp T &kp SPACE>; };
        m_level: m_level { compatible = "zmk,behavior-macro"; #binding-cells = <0>; wait-ms = <10>; tap-ms = <10>;
            bindings = <&kp L &kp E &kp V &kp E &kp L &kp SPACE>; };
        m_relationship: m_relationship { compatible = "zmk,behavior-macro"; #binding-cells = <0>; wait-ms = <10>; tap-ms = <10>;
            bindings = <&kp R &kp E &kp L &kp A &kp T &kp I &kp O &kp N &kp S &kp H &kp I &kp P &kp SPACE>; };
        m_material: m_material { compatible = "zmk,behavior-macro"; #binding-cells = <0>; wait-ms = <10>; tap-ms = <10>;
            bindings = <&kp M &kp A &kp T &kp E &kp R &kp I &kp A &kp L &kp SPACE>; };
        m_behavior: m_behavior { compatible = "zmk,behavior-macro"; #binding-cells = <0>; wait-ms = <10>; tap-ms = <10>;
            bindings = <&kp B &kp E &kp H &kp A &kp V &kp I &kp O &kp R &kp SPACE>; };
        m_view: m_view { compatible = "zmk,behavior-macro"; #binding-cells = <0>; wait-ms = <10>; tap-ms = <10>;
            bindings = <&kp V &kp I &kp E &kp W &kp SPACE>; };
        m_effect: m_effect { compatible = "zmk,behavior-macro"; #binding-cells = <0>; wait-ms = <10>; tap-ms = <10>;
            bindings = <&kp E &kp F &kp F &kp E &kp C &kp T &kp SPACE>; };
        m_policy: m_policy { compatible = "zmk,behavior-macro"; #binding-cells = <0>; wait-ms = <10>; tap-ms = <10>;
            bindings = <&kp P &kp O &kp L &kp I &kp C &kp Y &kp SPACE>; };
        m_field: m_field { compatible = "zmk,behavior-macro"; #binding-cells = <0>; wait-ms = <10>; tap-ms = <10>;
            bindings = <&kp F &kp I &kp E &kp L &kp D &kp SPACE>; };
        m_daughter: m_daughter { compatible = "zmk,behavior-macro"; #binding-cells = <0>; wait-ms = <10>; tap-ms = <10>;
            bindings = <&kp D &kp A &kp U &kp G &kp H &kp T &kp E &kp R &kp SPACE>; };
        m_teacher: m_teacher { compatible = "zmk,behavior-macro"; #binding-cells = <0>; wait-ms = <10>; tap-ms = <10>;
            bindings = <&kp T &kp E &kp A &kp C &kp H &kp E &kp R &kp SPACE>; };
        m_page: m_page { compatible = "zmk,behavior-macro"; #binding-cells = <0>; wait-ms = <10>; tap-ms = <10>;
            bindings = <&kp P &kp A &kp G &kp E &kp SPACE>; };
        m_force: m_force { compatible = "zmk,behavior-macro"; #binding-cells = <0>; wait-ms = <10>; tap-ms = <10>;
            bindings = <&kp F &kp O &kp R &kp C &kp E &kp SPACE>; };
        m_truth: m_truth { compatible = "zmk,behavior-macro"; #binding-cells = <0>; wait-ms = <10>; tap-ms = <10>;
            bindings = <&kp T &kp R &kp U &kp T &kp H &kp SPACE>; };
        m_value: m_value { compatible = "zmk,behavior-macro"; #binding-cells = <0>; wait-ms = <10>; tap-ms = <10>;
            bindings = <&kp V &kp A &kp L &kp U &kp E &kp SPACE>; };
        // === 2-key word macros (100 new) ===
    };

    combos {
        compatible = "zmk,combos";

        // === 2-key word combos (158) ===
        combo_the     { timeout-ms = <40>; require-prior-idle-ms = <150>; key-positions = <5 18>;  bindings = <&m_the>;     layers = <0>; };  // T+H
        combo_and     { timeout-ms = <40>; require-prior-idle-ms = <150>; key-positions = <13 30>; bindings = <&m_and>;     layers = <0>; };  // A+N
        combo_that    { timeout-ms = <40>; require-prior-idle-ms = <150>; key-positions = <5 13>;  bindings = <&m_that>;    layers = <0>; };  // T+A
        combo_have    { timeout-ms = <40>; require-prior-idle-ms = <150>; key-positions = <18 28>; bindings = <&m_have>;    layers = <0>; };  // H+V
        combo_with    { timeout-ms = <40>; require-prior-idle-ms = <150>; key-positions = <2 18>;  bindings = <&m_with>;    layers = <0>; };  // W+H
        combo_for     { timeout-ms = <40>; require-prior-idle-ms = <150>; key-positions = <16 9>;  bindings = <&m_for>;     layers = <0>; };  // F+O
        combo_not     { timeout-ms = <40>; require-prior-idle-ms = <150>; key-positions = <30 5>;  bindings = <&m_not>;     layers = <0>; };  // N+T
        combo_you     { timeout-ms = <40>; require-prior-idle-ms = <150>; key-positions = <6 7>;   bindings = <&m_you>;     layers = <0>; };  // Y+U
        combo_this    { timeout-ms = <40>; require-prior-idle-ms = <150>; key-positions = <5 14>;  bindings = <&m_this>;    layers = <0>; };  // T+S
        combo_but     { timeout-ms = <40>; require-prior-idle-ms = <150>; key-positions = <29 7>;  bindings = <&m_but>;     layers = <0>; };  // B+U
        combo_from    { timeout-ms = <40>; require-prior-idle-ms = <150>; key-positions = <16 31>; bindings = <&m_from>;    layers = <0>; };  // F+M
        combo_they    { timeout-ms = <40>; require-prior-idle-ms = <150>; key-positions = <5 6>;   bindings = <&m_they>;    layers = <0>; };  // T+Y
        combo_will    { timeout-ms = <40>; require-prior-idle-ms = <150>; key-positions = <2 21>;  bindings = <&m_will>;    layers = <0>; };  // W+L
        combo_would   { timeout-ms = <40>; require-prior-idle-ms = <150>; key-positions = <2 15>;  bindings = <&m_would>;   layers = <0>; };  // W+D
        combo_what    { timeout-ms = <40>; require-prior-idle-ms = <150>; key-positions = <2 13>;  bindings = <&m_what>;    layers = <0>; };  // W+A
        combo_about   { timeout-ms = <40>; require-prior-idle-ms = <150>; key-positions = <13 29>; bindings = <&m_about>;   layers = <0>; };  // A+B
        combo_which   { timeout-ms = <40>; require-prior-idle-ms = <150>; key-positions = <2 27>;  bindings = <&m_which>;   layers = <0>; };  // W+C
        combo_when    { timeout-ms = <40>; require-prior-idle-ms = <150>; key-positions = <2 30>;  bindings = <&m_when>;    layers = <0>; };  // W+N
        combo_just    { timeout-ms = <40>; require-prior-idle-ms = <150>; key-positions = <19 14>; bindings = <&m_just>;    layers = <0>; };  // J+S
        combo_know    { timeout-ms = <40>; require-prior-idle-ms = <150>; key-positions = <20 30>; bindings = <&m_know>;    layers = <0>; };  // K+N
        combo_like    { timeout-ms = <40>; require-prior-idle-ms = <150>; key-positions = <21 27>; bindings = <&m_like>;    layers = <0>; };  // L+C
        combo_your    { timeout-ms = <40>; require-prior-idle-ms = <150>; key-positions = <6 4>;   bindings = <&m_your>;    layers = <0>; };  // Y+R
        combo_could   { timeout-ms = <40>; require-prior-idle-ms = <150>; key-positions = <27 9>; bindings = <&m_could>;   layers = <0>; };  // C+O
        combo_should  { timeout-ms = <40>; require-prior-idle-ms = <150>; key-positions = <14 18>; bindings = <&m_should>;  layers = <0>; };  // S+H
        combo_before  { timeout-ms = <40>; require-prior-idle-ms = <150>; key-positions = <29 16>; bindings = <&m_before>;  layers = <0>; };  // B+F
        combo_because { timeout-ms = <40>; require-prior-idle-ms = <150>; key-positions = <29 27>; bindings = <&m_because>; layers = <0>; };  // B+C
        combo_think   { timeout-ms = <40>; require-prior-idle-ms = <150>; key-positions = <5 20>;  bindings = <&m_think>;   layers = <0>; };  // T+K
        combo_also    { timeout-ms = <40>; require-prior-idle-ms = <150>; key-positions = <13 21>; bindings = <&m_also>;    layers = <0>; };  // A+L
        combo_after   { timeout-ms = <40>; require-prior-idle-ms = <150>; key-positions = <13 16>; bindings = <&m_after>;   layers = <0>; };  // A+F
        combo_time    { timeout-ms = <40>; require-prior-idle-ms = <150>; key-positions = <5 31>;  bindings = <&m_time>;    layers = <0>; };  // T+M
        combo_again   { timeout-ms = <40>; require-prior-idle-ms = <150>; key-positions = <13 17>; bindings = <&m_again>;   layers = <0>; };  // A+G
        combo_some    { timeout-ms = <40>; require-prior-idle-ms = <150>; key-positions = <14 31>; bindings = <&m_some>;    layers = <0>; };  // S+M
        combo_good    { timeout-ms = <40>; require-prior-idle-ms = <150>; key-positions = <17 15>; bindings = <&m_good>;    layers = <0>; };  // G+D
        combo_more    { timeout-ms = <40>; require-prior-idle-ms = <150>; key-positions = <31 4>;  bindings = <&m_more>;    layers = <0>; };  // M+R
        combo_never   { timeout-ms = <40>; require-prior-idle-ms = <150>; key-positions = <30 28>; bindings = <&m_never>;   layers = <0>; };  // N+V
        combo_even    { timeout-ms = <40>; require-prior-idle-ms = <150>; key-positions = <3 28>;  bindings = <&m_even>;    layers = <0>; };  // E+V
        combo_very    { timeout-ms = <40>; require-prior-idle-ms = <150>; key-positions = <28 6>;  bindings = <&m_very>;    layers = <0>; };  // V+Y
        combo_work    { timeout-ms = <40>; require-prior-idle-ms = <150>; key-positions = <2 20>;  bindings = <&m_work>;    layers = <0>; };  // W+K
        combo_way     { timeout-ms = <40>; require-prior-idle-ms = <150>; key-positions = <2 6>;   bindings = <&m_way>;     layers = <0>; };  // W+Y
        combo_make    { timeout-ms = <40>; require-prior-idle-ms = <150>; key-positions = <31 20>; bindings = <&m_make>;    layers = <0>; };  // M+K
        combo_need    { timeout-ms = <40>; require-prior-idle-ms = <150>; key-positions = <30 15>; bindings = <&m_need>;    layers = <0>; };  // N+D
        combo_only    { timeout-ms = <40>; require-prior-idle-ms = <150>; key-positions = <30 21>; bindings = <&m_only>;    layers = <0>; };  // N+L
        combo_been    { timeout-ms = <40>; require-prior-idle-ms = <150>; key-positions = <29 30>; bindings = <&m_been>;    layers = <0>; };  // B+N
        combo_while   { timeout-ms = <40>; require-prior-idle-ms = <150>; key-positions = <18 21>; bindings = <&m_while>;   layers = <0>; };  // H+L
        combo_can     { timeout-ms = <40>; require-prior-idle-ms = <150>; key-positions = <27 30>; bindings = <&m_can>;     layers = <0>; };  // C+N
        combo_come    { timeout-ms = <40>; require-prior-idle-ms = <150>; key-positions = <27 31>; bindings = <&m_come>;    layers = <0>; };  // C+M
        combo_one     { timeout-ms = <40>; require-prior-idle-ms = <150>; key-positions = <9 3>;   bindings = <&m_one>;     layers = <0>; };  // O+E
        combo_great   { timeout-ms = <40>; require-prior-idle-ms = <150>; key-positions = <17 3>;  bindings = <&m_great>;   layers = <0>; };  // G+E
        combo_might   { timeout-ms = <40>; require-prior-idle-ms = <150>; key-positions = <31 17>; bindings = <&m_might>;   layers = <0>; };  // M+G
        combo_found   { timeout-ms = <40>; require-prior-idle-ms = <150>; key-positions = <16 30>; bindings = <&m_found>;   layers = <0>; };  // F+N
        combo_under   { timeout-ms = <40>; require-prior-idle-ms = <150>; key-positions = <7 15>;  bindings = <&m_under>;   layers = <0>; };  // U+D
        combo_other   { timeout-ms = <40>; require-prior-idle-ms = <150>; key-positions = <9 5>;   bindings = <&m_other>;   layers = <0>; };  // O+T
        combo_people  { timeout-ms = <40>; require-prior-idle-ms = <150>; key-positions = <10 3>;  bindings = <&m_people>;  layers = <0>; };  // P+E
        combo_really  { timeout-ms = <40>; require-prior-idle-ms = <150>; key-positions = <4 21>;  bindings = <&m_really>;  layers = <0>; };  // R+L
        combo_her     { timeout-ms = <40>; require-prior-idle-ms = <150>; key-positions = <18 4>;  bindings = <&m_her>;     layers = <0>; };  // H+R
        combo_his     { timeout-ms = <40>; require-prior-idle-ms = <150>; key-positions = <18 14>; bindings = <&m_his>;     layers = <0>; };  // H+S
        combo_are     { timeout-ms = <40>; require-prior-idle-ms = <150>; key-positions = <13 3>;  bindings = <&m_are>;     layers = <0>; };  // A+E
        combo_was     { timeout-ms = <40>; require-prior-idle-ms = <150>; key-positions = <13 14>;  bindings = <&m_was>;     layers = <0>; };  // A+S

        // === 2-key word combos (100 new) ===

        // === 3-key word combos — Common English (43) ===
        combo_said         { timeout-ms = <40>; require-prior-idle-ms = <150>; key-positions = <13 8>; bindings = <&m_said>; layers = <0>; };  // A+I
        combo_look         { timeout-ms = <40>; require-prior-idle-ms = <150>; key-positions = <9 20>; bindings = <&m_look>; layers = <0>; };  // O+K
        combo_want         { timeout-ms = <40>; require-prior-idle-ms = <150>; key-positions = <2 5>; bindings = <&m_want>; layers = <0>; };  // W+T
        combo_give         { timeout-ms = <40>; require-prior-idle-ms = <150>; key-positions = <8 3>; bindings = <&m_give>; layers = <0>; };  // I+E
        combo_find         { timeout-ms = <40>; require-prior-idle-ms = <150>; key-positions = <8 30>; bindings = <&m_find>; layers = <0>; };  // I+N
        combo_tell         { timeout-ms = <40>; require-prior-idle-ms = <150>; key-positions = <5 3>; bindings = <&m_tell>; layers = <0>; };  // T+E
        combo_seem         { timeout-ms = <40>; require-prior-idle-ms = <150>; key-positions = <14 3>; bindings = <&m_seem>; layers = <0>; };  // S+E
        combo_feel         { timeout-ms = <40>; require-prior-idle-ms = <150>; key-positions = <3 21>; bindings = <&m_feel>; layers = <0>; };  // E+L
        combo_leave        { timeout-ms = <40>; require-prior-idle-ms = <150>; key-positions = <13 28>; bindings = <&m_leave>; layers = <0>; };  // A+V
        combo_call         { timeout-ms = <40>; require-prior-idle-ms = <150>; key-positions = <27 13>; bindings = <&m_call>; layers = <0>; };  // C+A
        combo_start        { timeout-ms = <40>; require-prior-idle-ms = <150>; key-positions = <13 4>; bindings = <&m_start>; layers = <0>; };  // A+R
        combo_show         { timeout-ms = <40>; require-prior-idle-ms = <150>; key-positions = <14 9>; bindings = <&m_show>; layers = <0>; };  // S+O
        combo_hear         { timeout-ms = <40>; require-prior-idle-ms = <150>; key-positions = <3 4>; bindings = <&m_hear>; layers = <0>; };  // E+R
        combo_play         { timeout-ms = <40>; require-prior-idle-ms = <150>; key-positions = <10 13>; bindings = <&m_play>; layers = <0>; };  // P+A
        combo_move         { timeout-ms = <40>; require-prior-idle-ms = <150>; key-positions = <31 3>; bindings = <&m_move>; layers = <0>; };  // M+E
        combo_believe      { timeout-ms = <40>; require-prior-idle-ms = <150>; key-positions = <29 3>; bindings = <&m_believe>; layers = <0>; };  // B+E
        combo_hold         { timeout-ms = <40>; require-prior-idle-ms = <150>; key-positions = <9 15>; bindings = <&m_hold>; layers = <0>; };  // O+D
        combo_begin        { timeout-ms = <40>; require-prior-idle-ms = <150>; key-positions = <3 30>; bindings = <&m_begin>; layers = <0>; };  // E+N
        combo_talk         { timeout-ms = <40>; require-prior-idle-ms = <150>; key-positions = <5 21>; bindings = <&m_talk>; layers = <0>; };  // T+L
        combo_turn         { timeout-ms = <40>; require-prior-idle-ms = <150>; key-positions = <5 4>; bindings = <&m_turn>; layers = <0>; };  // T+R
        combo_must         { timeout-ms = <40>; require-prior-idle-ms = <150>; key-positions = <7 5>; bindings = <&m_must>; layers = <0>; };  // U+T
        combo_much         { timeout-ms = <40>; require-prior-idle-ms = <150>; key-positions = <7 27>; bindings = <&m_much>; layers = <0>; };  // U+C
        combo_many         { timeout-ms = <40>; require-prior-idle-ms = <150>; key-positions = <31 13>; bindings = <&m_many>; layers = <0>; };  // M+A
        combo_less         { timeout-ms = <40>; require-prior-idle-ms = <150>; key-positions = <21 14>; bindings = <&m_less>; layers = <0>; };  // L+S
        combo_number       { timeout-ms = <40>; require-prior-idle-ms = <150>; key-positions = <30 4>; bindings = <&m_number>; layers = <0>; };  // N+R
        combo_part         { timeout-ms = <40>; require-prior-idle-ms = <150>; key-positions = <10 4>; bindings = <&m_part>; layers = <0>; };  // P+R
        combo_place        { timeout-ms = <40>; require-prior-idle-ms = <150>; key-positions = <10 21>; bindings = <&m_place>; layers = <0>; };  // P+L
        combo_down         { timeout-ms = <40>; require-prior-idle-ms = <150>; key-positions = <9 30>; bindings = <&m_down>; layers = <0>; };  // O+N
        combo_left         { timeout-ms = <40>; require-prior-idle-ms = <150>; key-positions = <3 16>; bindings = <&m_left>; layers = <0>; };  // E+F
        combo_problem      { timeout-ms = <40>; require-prior-idle-ms = <150>; key-positions = <4 9>; bindings = <&m_problem>; layers = <0>; };  // R+O
        combo_hand         { timeout-ms = <40>; require-prior-idle-ms = <150>; key-positions = <13 15>; bindings = <&m_hand>; layers = <0>; };  // A+D
        combo_case         { timeout-ms = <40>; require-prior-idle-ms = <150>; key-positions = <27 14>; bindings = <&m_case>; layers = <0>; };  // C+S
        combo_early        { timeout-ms = <40>; require-prior-idle-ms = <150>; key-positions = <3 6>; bindings = <&m_early>; layers = <0>; };  // E+Y
        combo_change       { timeout-ms = <40>; require-prior-idle-ms = <150>; key-positions = <18 3>; bindings = <&m_change>; layers = <0>; };  // H+E
        combo_kind         { timeout-ms = <40>; require-prior-idle-ms = <150>; key-positions = <8 15>; bindings = <&m_kind>; layers = <0>; };  // I+D
        combo_next         { timeout-ms = <40>; require-prior-idle-ms = <150>; key-positions = <3 26>; bindings = <&m_next>; layers = <0>; };  // E+X
        combo_both         { timeout-ms = <40>; require-prior-idle-ms = <150>; key-positions = <29 9>; bindings = <&m_both>; layers = <0>; };  // B+O
        combo_social       { timeout-ms = <40>; require-prior-idle-ms = <150>; key-positions = <9 13>; bindings = <&m_social>; layers = <0>; };  // O+A
        combo_doing        { timeout-ms = <40>; require-prior-idle-ms = <150>; key-positions = <9 8>; bindings = <&m_doing>; layers = <0>; };  // O+I
        combo_going        { timeout-ms = <40>; require-prior-idle-ms = <150>; key-positions = <17 8>; bindings = <&m_going>; layers = <0>; };  // G+I
        combo_name_word    { timeout-ms = <40>; require-prior-idle-ms = <150>; key-positions = <30 31>; bindings = <m_name>; layers = <0>; };  // N+M (renamed to avoid combo-name conflict)
        combo_possible     { timeout-ms = <40>; require-prior-idle-ms = <150>; key-positions = <14 8>; bindings = <&m_possible>; layers = <0>; };  // S+I
        combo_general      { timeout-ms = <40>; require-prior-idle-ms = <150>; key-positions = <17 4>; bindings = <&m_general>; layers = <0>; };  // G+R
        combo_school       { timeout-ms = <40>; require-prior-idle-ms = <150>; key-positions = <18 9>; bindings = <&m_school>; layers = <0>; };  // H+O
        combo_high         { timeout-ms = <40>; require-prior-idle-ms = <150>; key-positions = <18 8>; bindings = <&m_high>; layers = <0>; };  // H+I
        combo_business     { timeout-ms = <40>; require-prior-idle-ms = <150>; key-positions = <7 3>; bindings = <&m_business>; layers = <0>; };  // U+E
        combo_issue        { timeout-ms = <40>; require-prior-idle-ms = <150>; key-positions = <8 7>; bindings = <&m_issue>; layers = <0>; };  // I+U
        combo_side         { timeout-ms = <40>; require-prior-idle-ms = <150>; key-positions = <14 15>; bindings = <&m_side>; layers = <0>; };  // S+D
        combo_public       { timeout-ms = <40>; require-prior-idle-ms = <150>; key-positions = <10 8>; bindings = <&m_public>; layers = <0>; };  // P+I
        combo_market       { timeout-ms = <40>; require-prior-idle-ms = <150>; key-positions = <13 20>; bindings = <&m_market>; layers = <0>; };  // A+K
        combo_program      { timeout-ms = <40>; require-prior-idle-ms = <150>; key-positions = <10 9>; bindings = <&m_program>; layers = <0>; };  // P+O
        combo_question     { timeout-ms = <40>; require-prior-idle-ms = <150>; key-positions = <7 9>; bindings = <&m_question>; layers = <0>; };  // U+O
        combo_government   { timeout-ms = <40>; require-prior-idle-ms = <150>; key-positions = <17 9>; bindings = <&m_government>; layers = <0>; };  // G+O
        combo_company      { timeout-ms = <40>; require-prior-idle-ms = <150>; key-positions = <9 31>; bindings = <&m_company>; layers = <0>; };  // O+M
        combo_week         { timeout-ms = <40>; require-prior-idle-ms = <150>; key-positions = <2 3>; bindings = <&m_week>; layers = <0>; };  // W+E
        combo_family       { timeout-ms = <40>; require-prior-idle-ms = <150>; key-positions = <8 21>; bindings = <&m_family>; layers = <0>; };  // I+L
        combo_service      { timeout-ms = <40>; require-prior-idle-ms = <150>; key-positions = <14 4>; bindings = <&m_service>; layers = <0>; };  // S+R
        combo_friend       { timeout-ms = <40>; require-prior-idle-ms = <150>; key-positions = <4 8>; bindings = <&m_friend>; layers = <0>; };  // R+I
        combo_price        { timeout-ms = <40>; require-prior-idle-ms = <150>; key-positions = <4 27>; bindings = <&m_price>; layers = <0>; };  // R+C
        combo_report       { timeout-ms = <40>; require-prior-idle-ms = <150>; key-positions = <10 5>; bindings = <&m_report>; layers = <0>; };  // P+T
        combo_decision     { timeout-ms = <40>; require-prior-idle-ms = <150>; key-positions = <27 8>; bindings = <&m_decision>; layers = <0>; };  // C+I
        combo_parent       { timeout-ms = <40>; require-prior-idle-ms = <150>; key-positions = <10 30>; bindings = <&m_parent>; layers = <0>; };  // P+N
        combo_situation    { timeout-ms = <40>; require-prior-idle-ms = <150>; key-positions = <8 5>; bindings = <&m_situation>; layers = <0>; };  // I+T
        combo_develop      { timeout-ms = <40>; require-prior-idle-ms = <150>; key-positions = <15 21>; bindings = <&m_develop>; layers = <0>; };  // D+L
        combo_system       { timeout-ms = <40>; require-prior-idle-ms = <150>; key-positions = <14 6>; bindings = <&m_system>; layers = <0>; };  // S+Y
        combo_product      { timeout-ms = <40>; require-prior-idle-ms = <150>; key-positions = <4 7>; bindings = <&m_product>; layers = <0>; };  // R+U
        combo_student      { timeout-ms = <40>; require-prior-idle-ms = <150>; key-positions = <14 7>; bindings = <&m_student>; layers = <0>; };  // S+U
        combo_process      { timeout-ms = <40>; require-prior-idle-ms = <150>; key-positions = <10 14>; bindings = <&m_process>; layers = <0>; };  // P+S
        combo_method       { timeout-ms = <40>; require-prior-idle-ms = <150>; key-positions = <5 15>; bindings = <&m_method>; layers = <0>; };  // T+D
        combo_research     { timeout-ms = <40>; require-prior-idle-ms = <150>; key-positions = <13 18>; bindings = <&m_research>; layers = <0>; };  // A+H
        combo_water        { timeout-ms = <40>; require-prior-idle-ms = <150>; key-positions = <2 4>; bindings = <&m_water>; layers = <0>; };  // W+R
        combo_article      { timeout-ms = <40>; require-prior-idle-ms = <150>; key-positions = <5 27>; bindings = <&m_article>; layers = <0>; };  // T+C
        combo_support      { timeout-ms = <40>; require-prior-idle-ms = <150>; key-positions = <7 10>; bindings = <&m_support>; layers = <0>; };  // U+P
        combo_evidence     { timeout-ms = <40>; require-prior-idle-ms = <150>; key-positions = <28 8>; bindings = <&m_evidence>; layers = <0>; };  // V+I
        combo_activity     { timeout-ms = <40>; require-prior-idle-ms = <150>; key-positions = <13 6>; bindings = <&m_activity>; layers = <0>; };  // A+Y
        combo_nature       { timeout-ms = <40>; require-prior-idle-ms = <150>; key-positions = <13 7>; bindings = <&m_nature>; layers = <0>; };  // A+U
        combo_theory       { timeout-ms = <40>; require-prior-idle-ms = <150>; key-positions = <9 6>; bindings = <&m_theory>; layers = <0>; };  // O+Y
        combo_history      { timeout-ms = <40>; require-prior-idle-ms = <150>; key-positions = <8 6>; bindings = <&m_history>; layers = <0>; };  // I+Y
        combo_quality      { timeout-ms = <40>; require-prior-idle-ms = <150>; key-positions = <7 21>; bindings = <&m_quality>; layers = <0>; };  // U+L
        combo_security     { timeout-ms = <40>; require-prior-idle-ms = <150>; key-positions = <27 6>; bindings = <&m_security>; layers = <0>; };  // C+Y
        combo_economy      { timeout-ms = <40>; require-prior-idle-ms = <150>; key-positions = <31 6>; bindings = <&m_economy>; layers = <0>; };  // M+Y
        combo_industry     { timeout-ms = <40>; require-prior-idle-ms = <150>; key-positions = <15 4>; bindings = <&m_industry>; layers = <0>; };  // D+R
        combo_media        { timeout-ms = <40>; require-prior-idle-ms = <150>; key-positions = <31 8>; bindings = <&m_media>; layers = <0>; };  // M+I
        combo_practice     { timeout-ms = <40>; require-prior-idle-ms = <150>; key-positions = <10 27>; bindings = <&m_practice>; layers = <0>; };  // P+C
        combo_education    { timeout-ms = <40>; require-prior-idle-ms = <150>; key-positions = <7 30>; bindings = <&m_education>; layers = <0>; };  // U+N
        combo_management   { timeout-ms = <40>; require-prior-idle-ms = <150>; key-positions = <30 17>; bindings = <&m_management>; layers = <0>; };  // N+G
        combo_level        { timeout-ms = <40>; require-prior-idle-ms = <150>; key-positions = <21 28>; bindings = <&m_level>; layers = <0>; };  // L+V
        combo_relationship { timeout-ms = <40>; require-prior-idle-ms = <150>; key-positions = <18 10>; bindings = <&m_relationship>; layers = <0>; };  // H+P
        combo_material     { timeout-ms = <40>; require-prior-idle-ms = <150>; key-positions = <31 21>; bindings = <&m_material>; layers = <0>; };  // M+L
        combo_behavior     { timeout-ms = <40>; require-prior-idle-ms = <150>; key-positions = <29 4>; bindings = <&m_behavior>; layers = <0>; };  // B+R
        combo_view         { timeout-ms = <40>; require-prior-idle-ms = <150>; key-positions = <8 2>; bindings = <&m_view>; layers = <0>; };  // I+W
        combo_effect       { timeout-ms = <40>; require-prior-idle-ms = <150>; key-positions = <16 5>; bindings = <&m_effect>; layers = <0>; };  // F+T
        combo_policy       { timeout-ms = <40>; require-prior-idle-ms = <150>; key-positions = <21 6>; bindings = <&m_policy>; layers = <0>; };  // L+Y
        combo_field        { timeout-ms = <40>; require-prior-idle-ms = <150>; key-positions = <16 8>; bindings = <&m_field>; layers = <0>; };  // F+I
        combo_daughter     { timeout-ms = <40>; require-prior-idle-ms = <150>; key-positions = <15 18>; bindings = <&m_daughter>; layers = <0>; };  // D+H
        combo_teacher      { timeout-ms = <40>; require-prior-idle-ms = <150>; key-positions = <27 18>; bindings = <&m_teacher>; layers = <0>; };  // C+H
        combo_page         { timeout-ms = <40>; require-prior-idle-ms = <150>; key-positions = <10 17>; bindings = <&m_page>; layers = <0>; };  // P+G
        combo_force        { timeout-ms = <40>; require-prior-idle-ms = <150>; key-positions = <16 27>; bindings = <&m_force>; layers = <0>; };  // F+C
        combo_truth        { timeout-ms = <40>; require-prior-idle-ms = <150>; key-positions = <7 18>; bindings = <&m_truth>; layers = <0>; };  // U+H
        combo_value        { timeout-ms = <40>; require-prior-idle-ms = <150>; key-positions = <28 7>; bindings = <&m_value>; layers = <0>; };  // V+U
        combo_through   { timeout-ms = <40>; require-prior-idle-ms = <150>; key-positions = <5 18 4>;   bindings = <&m_through>;   layers = <0>; };  // T+H+R
        combo_there     { timeout-ms = <40>; require-prior-idle-ms = <150>; key-positions = <5 18 3>;   bindings = <&m_there>;     layers = <0>; };  // T+H+E
        combo_than      { timeout-ms = <40>; require-prior-idle-ms = <150>; key-positions = <5 18 13>;  bindings = <&m_than>;      layers = <0>; };  // T+H+A
        combo_their     { timeout-ms = <40>; require-prior-idle-ms = <150>; key-positions = <5 18 8>;   bindings = <&m_their>;     layers = <0>; };  // T+H+I
        combo_those     { timeout-ms = <40>; require-prior-idle-ms = <150>; key-positions = <5 18 9>;   bindings = <&m_those>;     layers = <0>; };  // T+H+O
        combo_thing     { timeout-ms = <40>; require-prior-idle-ms = <150>; key-positions = <18 8 17>;  bindings = <&m_thing>;     layers = <0>; };  // H+I+G
        combo_though    { timeout-ms = <40>; require-prior-idle-ms = <150>; key-positions = <5 18 7>;   bindings = <&m_though>;    layers = <0>; };  // T+H+U
        combo_three     { timeout-ms = <40>; require-prior-idle-ms = <150>; key-positions = <5 4 3>;    bindings = <&m_three>;     layers = <0>; };  // T+R+E
        combo_together  { timeout-ms = <40>; require-prior-idle-ms = <150>; key-positions = <5 9 4>;   bindings = <&m_together>;  layers = <0>; };  // T+O+R
        combo_another   { timeout-ms = <40>; require-prior-idle-ms = <150>; key-positions = <13 30 5>;  bindings = <&m_another>;   layers = <0>; };  // A+N+T
        combo_where     { timeout-ms = <40>; require-prior-idle-ms = <150>; key-positions = <2 18 4>;   bindings = <&m_where>;     layers = <0>; };  // W+H+R
        combo_whether   { timeout-ms = <40>; require-prior-idle-ms = <150>; key-positions = <2 18 5>;   bindings = <&m_whether>;   layers = <0>; };  // W+H+T
        combo_between   { timeout-ms = <40>; require-prior-idle-ms = <150>; key-positions = <29 3 30>;  bindings = <&m_between>;   layers = <0>; };  // B+E+N
        combo_something { timeout-ms = <40>; require-prior-idle-ms = <150>; key-positions = <14 31 5>;  bindings = <&m_something>; layers = <0>; };  // S+M+T
        combo_already   { timeout-ms = <40>; require-prior-idle-ms = <150>; key-positions = <13 4 15>;  bindings = <&m_already>;   layers = <0>; };  // A+R+D
        combo_always    { timeout-ms = <40>; require-prior-idle-ms = <150>; key-positions = <13 21 2>;  bindings = <&m_always>;    layers = <0>; };  // A+L+W
        combo_around    { timeout-ms = <40>; require-prior-idle-ms = <150>; key-positions = <13 4 30>;  bindings = <&m_around>;    layers = <0>; };  // A+R+N
        combo_different { timeout-ms = <40>; require-prior-idle-ms = <150>; key-positions = <15 8 4>;  bindings = <&m_different>; layers = <0>; };  // D+I+R
        combo_important { timeout-ms = <40>; require-prior-idle-ms = <150>; key-positions = <31 10 4>;  bindings = <&m_important>; layers = <0>; };  // M+P+R
        combo_still     { timeout-ms = <40>; require-prior-idle-ms = <150>; key-positions = <14 5 21>;  bindings = <&m_still>;     layers = <0>; };  // S+T+L
        combo_every     { timeout-ms = <40>; require-prior-idle-ms = <150>; key-positions = <3 28 6>;   bindings = <&m_every>;     layers = <0>; };  // E+V+Y
        combo_first     { timeout-ms = <40>; require-prior-idle-ms = <150>; key-positions = <16 8 14>;  bindings = <&m_first>;     layers = <0>; };  // F+I+S
        combo_world     { timeout-ms = <40>; require-prior-idle-ms = <150>; key-positions = <2 4 21>;   bindings = <&m_world>;     layers = <0>; };  // W+R+L
        combo_little    { timeout-ms = <40>; require-prior-idle-ms = <150>; key-positions = <21 5 8>;   bindings = <&m_little>;    layers = <0>; };  // L+T+I
        combo_right     { timeout-ms = <40>; require-prior-idle-ms = <150>; key-positions = <4 8 17>;   bindings = <&m_right>;     layers = <0>; };  // R+I+G
        combo_being     { timeout-ms = <40>; require-prior-idle-ms = <150>; key-positions = <29 8 30>; bindings = <&m_being>;     layers = <0>; };  // B+I+N
        combo_small     { timeout-ms = <40>; require-prior-idle-ms = <150>; key-positions = <14 31 21>; bindings = <&m_small>;     layers = <0>; };  // S+M+L
        combo_take      { timeout-ms = <40>; require-prior-idle-ms = <150>; key-positions = <5 13 20>;  bindings = <&m_take>;      layers = <0>; };  // T+A+K
        combo_well      { timeout-ms = <40>; require-prior-idle-ms = <150>; key-positions = <2 3 21>;   bindings = <&m_well>;      layers = <0>; };  // W+E+L
        combo_into      { timeout-ms = <40>; require-prior-idle-ms = <150>; key-positions = <8 30 5>;   bindings = <&m_into>;      layers = <0>; };  // I+N+T
        combo_here      { timeout-ms = <40>; require-prior-idle-ms = <150>; key-positions = <18 3 4>;   bindings = <&m_here>;      layers = <0>; };  // H+E+R
        combo_since     { timeout-ms = <40>; require-prior-idle-ms = <150>; key-positions = <14 8 30>;  bindings = <&m_since>;     layers = <0>; };  // S+I+N
        combo_story     { timeout-ms = <40>; require-prior-idle-ms = <150>; key-positions = <14 5 4>;   bindings = <&m_story>;     layers = <0>; };  // S+T+R
        combo_write     { timeout-ms = <40>; require-prior-idle-ms = <150>; key-positions = <2 4 5>;    bindings = <&m_write>;     layers = <0>; };  // W+R+T
        combo_using     { timeout-ms = <40>; require-prior-idle-ms = <150>; key-positions = <7 14 30>;  bindings = <&m_using>;     layers = <0>; };  // U+S+N
        combo_actually  { timeout-ms = <40>; require-prior-idle-ms = <150>; key-positions = <13 27 21>; bindings = <&m_actually>;  layers = <0>; };  // A+C+L
        combo_learn     { timeout-ms = <40>; require-prior-idle-ms = <150>; key-positions = <21 4 30>;  bindings = <&m_learn>;     layers = <0>; };  // L+R+N
        combo_point     { timeout-ms = <40>; require-prior-idle-ms = <150>; key-positions = <10 30 5>;  bindings = <&m_point>;     layers = <0>; };  // P+N+T
        combo_long      { timeout-ms = <40>; require-prior-idle-ms = <150>; key-positions = <9 30 17>;  bindings = <&m_long>;      layers = <0>; };  // O+N+G
        combo_keep      { timeout-ms = <40>; require-prior-idle-ms = <150>; key-positions = <20 3 10>;  bindings = <&m_keep>;      layers = <0>; };  // K+E+P
        combo_same      { timeout-ms = <40>; require-prior-idle-ms = <150>; key-positions = <14 13 31>; bindings = <&m_same>;      layers = <0>; };  // S+A+M
        combo_each      { timeout-ms = <40>; require-prior-idle-ms = <150>; key-positions = <3 13 18>;  bindings = <&m_each>;      layers = <0>; };  // E+A+H
        combo_help      { timeout-ms = <40>; require-prior-idle-ms = <150>; key-positions = <18 21 10>; bindings = <&m_help>;      layers = <0>; };  // H+L+P

        // === 3-key word combos — ML/AI (23) ===
        combo_diffusion     { timeout-ms = <40>; require-prior-idle-ms = <150>; key-positions = <15 16 30>;  bindings = <&m_diffusion>;     layers = <0>; };  // D+F+N
        combo_embedding     { timeout-ms = <40>; require-prior-idle-ms = <150>; key-positions = <3 31 29>;   bindings = <&m_embedding>;     layers = <0>; };  // E+M+B
        combo_gradient      { timeout-ms = <40>; require-prior-idle-ms = <150>; key-positions = <17 4 15>;   bindings = <&m_gradient>;      layers = <0>; };  // G+R+D
        combo_inference     { timeout-ms = <40>; require-prior-idle-ms = <150>; key-positions = <8 30 16>;   bindings = <&m_inference>;     layers = <0>; };  // I+N+F
        combo_training      { timeout-ms = <40>; require-prior-idle-ms = <150>; key-positions = <5 4 30>;    bindings = <&m_training>;      layers = <0>; };  // T+R+N
        combo_activation    { timeout-ms = <40>; require-prior-idle-ms = <150>; key-positions = <13 27 5>;   bindings = <&m_activation>;    layers = <0>; };  // A+C+T
        combo_backprop      { timeout-ms = <40>; require-prior-idle-ms = <150>; key-positions = <29 10 4>;   bindings = <&m_backprop>;      layers = <0>; };  // B+P+R
        combo_neural        { timeout-ms = <40>; require-prior-idle-ms = <150>; key-positions = <30 4 21>;   bindings = <&m_neural>;        layers = <0>; };  // N+R+L
        combo_dropout       { timeout-ms = <40>; require-prior-idle-ms = <150>; key-positions = <15 4 10>;   bindings = <&m_dropout>;       layers = <0>; };  // D+R+P
        combo_dataset       { timeout-ms = <40>; require-prior-idle-ms = <150>; key-positions = <15 14 5>;   bindings = <&m_dataset>;       layers = <0>; };  // D+S+T
        combo_tokenize      { timeout-ms = <40>; require-prior-idle-ms = <150>; key-positions = <5 20 30>;   bindings = <&m_tokenize>;      layers = <0>; };  // T+K+N
        combo_latent        { timeout-ms = <40>; require-prior-idle-ms = <150>; key-positions = <21 5 30>;   bindings = <&m_latent>;        layers = <0>; };  // L+T+N
        combo_softmax       { timeout-ms = <40>; require-prior-idle-ms = <150>; key-positions = <14 16 31>;  bindings = <&m_softmax>;       layers = <0>; };  // S+F+M
        combo_residual      { timeout-ms = <40>; require-prior-idle-ms = <150>; key-positions = <4 14 15>;   bindings = <&m_residual>;      layers = <0>; };  // R+S+D
        combo_checkpoint    { timeout-ms = <40>; require-prior-idle-ms = <150>; key-positions = <27 20 10>;  bindings = <&m_checkpoint>;    layers = <0>; };  // C+K+P
        combo_logit         { timeout-ms = <40>; require-prior-idle-ms = <150>; key-positions = <21 17 8>;   bindings = <&m_logit>;         layers = <0>; };  // L+G+I
        combo_epoch         { timeout-ms = <40>; require-prior-idle-ms = <150>; key-positions = <3 10 9>;   bindings = <&m_epoch>;         layers = <0>; };  // E+P+O
        combo_batch         { timeout-ms = <40>; require-prior-idle-ms = <150>; key-positions = <29 13 27>;   bindings = <&m_batch>;         layers = <0>; };  // B+A+C
        combo_model         { timeout-ms = <40>; require-prior-idle-ms = <150>; key-positions = <31 15 21>;  bindings = <&m_model>;         layers = <0>; };  // M+D+L
        combo_language      { timeout-ms = <40>; require-prior-idle-ms = <150>; key-positions = <21 30 17>;  bindings = <&m_language>;       layers = <0>; };  // L+N+G
        combo_parameter     { timeout-ms = <40>; require-prior-idle-ms = <150>; key-positions = <10 4 31>;   bindings = <&m_parameter>;     layers = <0>; };  // P+R+M
        combo_mamba         { timeout-ms = <40>; require-prior-idle-ms = <150>; key-positions = <31 13 29>;  bindings = <&m_mamba>;         layers = <0>; };  // M+A+B
        combo_convolutional { timeout-ms = <40>; require-prior-idle-ms = <150>; key-positions = <27 30 28>;  bindings = <&m_convolutional>; layers = <0>; };  // C+N+V

        // === 3-key word combos — Rust (13) ===
        combo_trait    { timeout-ms = <40>; require-prior-idle-ms = <150>; key-positions = <5 4 13>;   bindings = <&m_trait>;    layers = <0>; };  // T+R+A
        combo_await    { timeout-ms = <40>; require-prior-idle-ms = <150>; key-positions = <13 2 5>;   bindings = <&m_await>;    layers = <0>; };  // A+W+T
        combo_impl     { timeout-ms = <40>; require-prior-idle-ms = <150>; key-positions = <8 31 21>;  bindings = <&m_impl>;     layers = <0>; };  // I+M+L
        combo_result   { timeout-ms = <40>; require-prior-idle-ms = <150>; key-positions = <4 14 21>;  bindings = <&m_result>;   layers = <0>; };  // R+S+L
        combo_option   { timeout-ms = <40>; require-prior-idle-ms = <150>; key-positions = <9 5 30>;   bindings = <&m_option>;   layers = <0>; };  // O+T+N
        combo_enum     { timeout-ms = <40>; require-prior-idle-ms = <150>; key-positions = <3 30 31>;  bindings = <&m_enum>;     layers = <0>; };  // E+N+M
        combo_match    { timeout-ms = <40>; require-prior-idle-ms = <150>; key-positions = <31 5 27>;  bindings = <&m_match>;    layers = <0>; };  // M+T+C
        combo_return   { timeout-ms = <40>; require-prior-idle-ms = <150>; key-positions = <4 3 5>;    bindings = <&m_return>;   layers = <0>; };  // R+E+T
        combo_derive   { timeout-ms = <40>; require-prior-idle-ms = <150>; key-positions = <15 4 8>;  bindings = <&m_derive>;   layers = <0>; };  // D+R+I
        combo_closure  { timeout-ms = <40>; require-prior-idle-ms = <150>; key-positions = <27 21 14>; bindings = <&m_closure>;  layers = <0>; };  // C+L+S
        combo_lifetime { timeout-ms = <40>; require-prior-idle-ms = <150>; key-positions = <21 16 5>;  bindings = <&m_lifetime>; layers = <0>; };  // L+F+T
        combo_borrow   { timeout-ms = <40>; require-prior-idle-ms = <150>; key-positions = <29 4 2>;   bindings = <&m_borrow>;   layers = <0>; };  // B+R+W
        combo_mut      { timeout-ms = <40>; require-prior-idle-ms = <150>; key-positions = <31 5 30>;   bindings = <&m_mut>;      layers = <0>; };  // M+T+N

        // === 3-key word combos — Haskell (6) ===
        combo_monad     { timeout-ms = <40>; require-prior-idle-ms = <150>; key-positions = <31 30 15>; bindings = <&m_monad>;     layers = <0>; };  // M+N+D
        combo_functor   { timeout-ms = <40>; require-prior-idle-ms = <150>; key-positions = <16 27 5>;  bindings = <&m_functor>;   layers = <0>; };  // F+C+T
        combo_maybe     { timeout-ms = <40>; require-prior-idle-ms = <150>; key-positions = <31 13 6>;  bindings = <&m_maybe>;     layers = <0>; };  // M+A+Y
        combo_monoid    { timeout-ms = <40>; require-prior-idle-ms = <150>; key-positions = <31 30 8>;  bindings = <&m_monoid>;    layers = <0>; };  // M+N+I
        combo_lambda    { timeout-ms = <40>; require-prior-idle-ms = <150>; key-positions = <21 31 29>; bindings = <&m_lambda>;    layers = <0>; };  // L+M+B
        combo_typeclass { timeout-ms = <40>; require-prior-idle-ms = <150>; key-positions = <5 10 27>;  bindings = <&m_typeclass>; layers = <0>; };  // T+P+C

        // === 3-key word combos — Other (6) ===
        combo_function { timeout-ms = <40>; require-prior-idle-ms = <150>; key-positions = <16 30 27>; bindings = <&m_function>; layers = <0>; };  // F+N+C
        combo_claude   { timeout-ms = <40>; require-prior-idle-ms = <150>; key-positions = <27 21 13>; bindings = <&m_claude>;   layers = <0>; };  // C+L+A
        combo_anthropic { timeout-ms = <40>; require-prior-idle-ms = <150>; key-positions = <13 5 10>; bindings = <&m_anthropic>; layers = <0>; };  // A+T+P
        combo_azure    { timeout-ms = <40>; require-prior-idle-ms = <150>; key-positions = <13 7 4>;  bindings = <&m_azure>;    layers = <0>; };  // A+U+R
        combo_duckdb   { timeout-ms = <40>; require-prior-idle-ms = <150>; key-positions = <15 7 20>; bindings = <&m_duckdb>;   layers = <0>; };  // D+U+K
        combo_iceberg  { timeout-ms = <40>; require-prior-idle-ms = <150>; key-positions = <8 27 29>;  bindings = <&m_iceberg>;  layers = <0>; };  // I+C+B

        // === 4-key word combos (10) ===
        combo_transformer     { timeout-ms = <40>; require-prior-idle-ms = <150>; key-positions = <5 4 13 30>;   bindings = <&m_transformer>;     layers = <0>; };  // T+R+A+N
        combo_quantization    { timeout-ms = <40>; require-prior-idle-ms = <150>; key-positions = <20 2 30 5>;   bindings = <&m_quantization>;    layers = <0>; };  // K+W+N+T
        combo_implementation  { timeout-ms = <40>; require-prior-idle-ms = <150>; key-positions = <8 31 10 21>;  bindings = <&m_implementation>;  layers = <0>; };  // I+M+P+L
        combo_struct          { timeout-ms = <40>; require-prior-idle-ms = <150>; key-positions = <14 5 4 27>;   bindings = <&m_struct>;          layers = <0>; };  // S+T+R+C
        combo_async           { timeout-ms = <40>; require-prior-idle-ms = <150>; key-positions = <13 14 30 27>; bindings = <&m_async>;           layers = <0>; };  // A+S+N+C
        combo_haskell         { timeout-ms = <40>; require-prior-idle-ms = <150>; key-positions = <18 14 20 21>; bindings = <&m_haskell>;         layers = <0>; };  // H+S+K+L
        combo_forall          { timeout-ms = <40>; require-prior-idle-ms = <150>; key-positions = <16 9 13 30>;  bindings = <&m_forall>;          layers = <0>; };  // F+O+A+N
        combo_skinly          { timeout-ms = <40>; require-prior-idle-ms = <150>; key-positions = <14 20 30 21>; bindings = <&m_skinly>;          layers = <0>; };  // S+K+N+L
        combo_beiersdorf      { timeout-ms = <40>; require-prior-idle-ms = <150>; key-positions = <29 3 8 4>;  bindings = <&m_beiersdorf>;      layers = <0>; };  // B+E+I+R
        combo_architecture    { timeout-ms = <40>; require-prior-idle-ms = <150>; key-positions = <13 4 27 18>;  bindings = <&m_architecture>;    layers = <0>; };  // A+R+C+H

        // === Utility combos (10) — no require-prior-idle for responsiveness ===
        combo_esc   { timeout-ms = <30>; key-positions = <19 20>; bindings = <&kp ESC>;    layers = <0>; };  // J+K
        combo_tab1  { timeout-ms = <30>; key-positions = <15 16>; bindings = <&kp TAB>;    layers = <0>; };  // D+F
        combo_tab2  { timeout-ms = <30>; key-positions = <20 21>; bindings = <&kp TAB>;    layers = <0>; };  // K+L
        combo_caps  { timeout-ms = <30>; key-positions = <2 16>;  bindings = <&caps_word>; layers = <0>; };  // W+F
        combo_lpar  { timeout-ms = <30>; key-positions = <7 8>;   bindings = <&kp LPAR>;   layers = <0>; };  // U+I
        combo_rpar  { timeout-ms = <30>; key-positions = <8 9>;   bindings = <&kp RPAR>;   layers = <0>; };  // I+O
        combo_lbkt  { timeout-ms = <30>; key-positions = <18 19>; bindings = <&kp LBKT>;   layers = <0>; };  // H+J
        combo_rbkt  { timeout-ms = <30>; key-positions = <19 21>; bindings = <&kp RBKT>;   layers = <0>; };  // J+L
        combo_ret   { timeout-ms = <30>; key-positions = <30 31>; bindings = <&kp RET>;    layers = <0>; };  // N+M
        combo_bspc  { timeout-ms = <30>; key-positions = <18 31>; bindings = <&kp BSPC>;   layers = <0>; };  // H+M
    };
};
